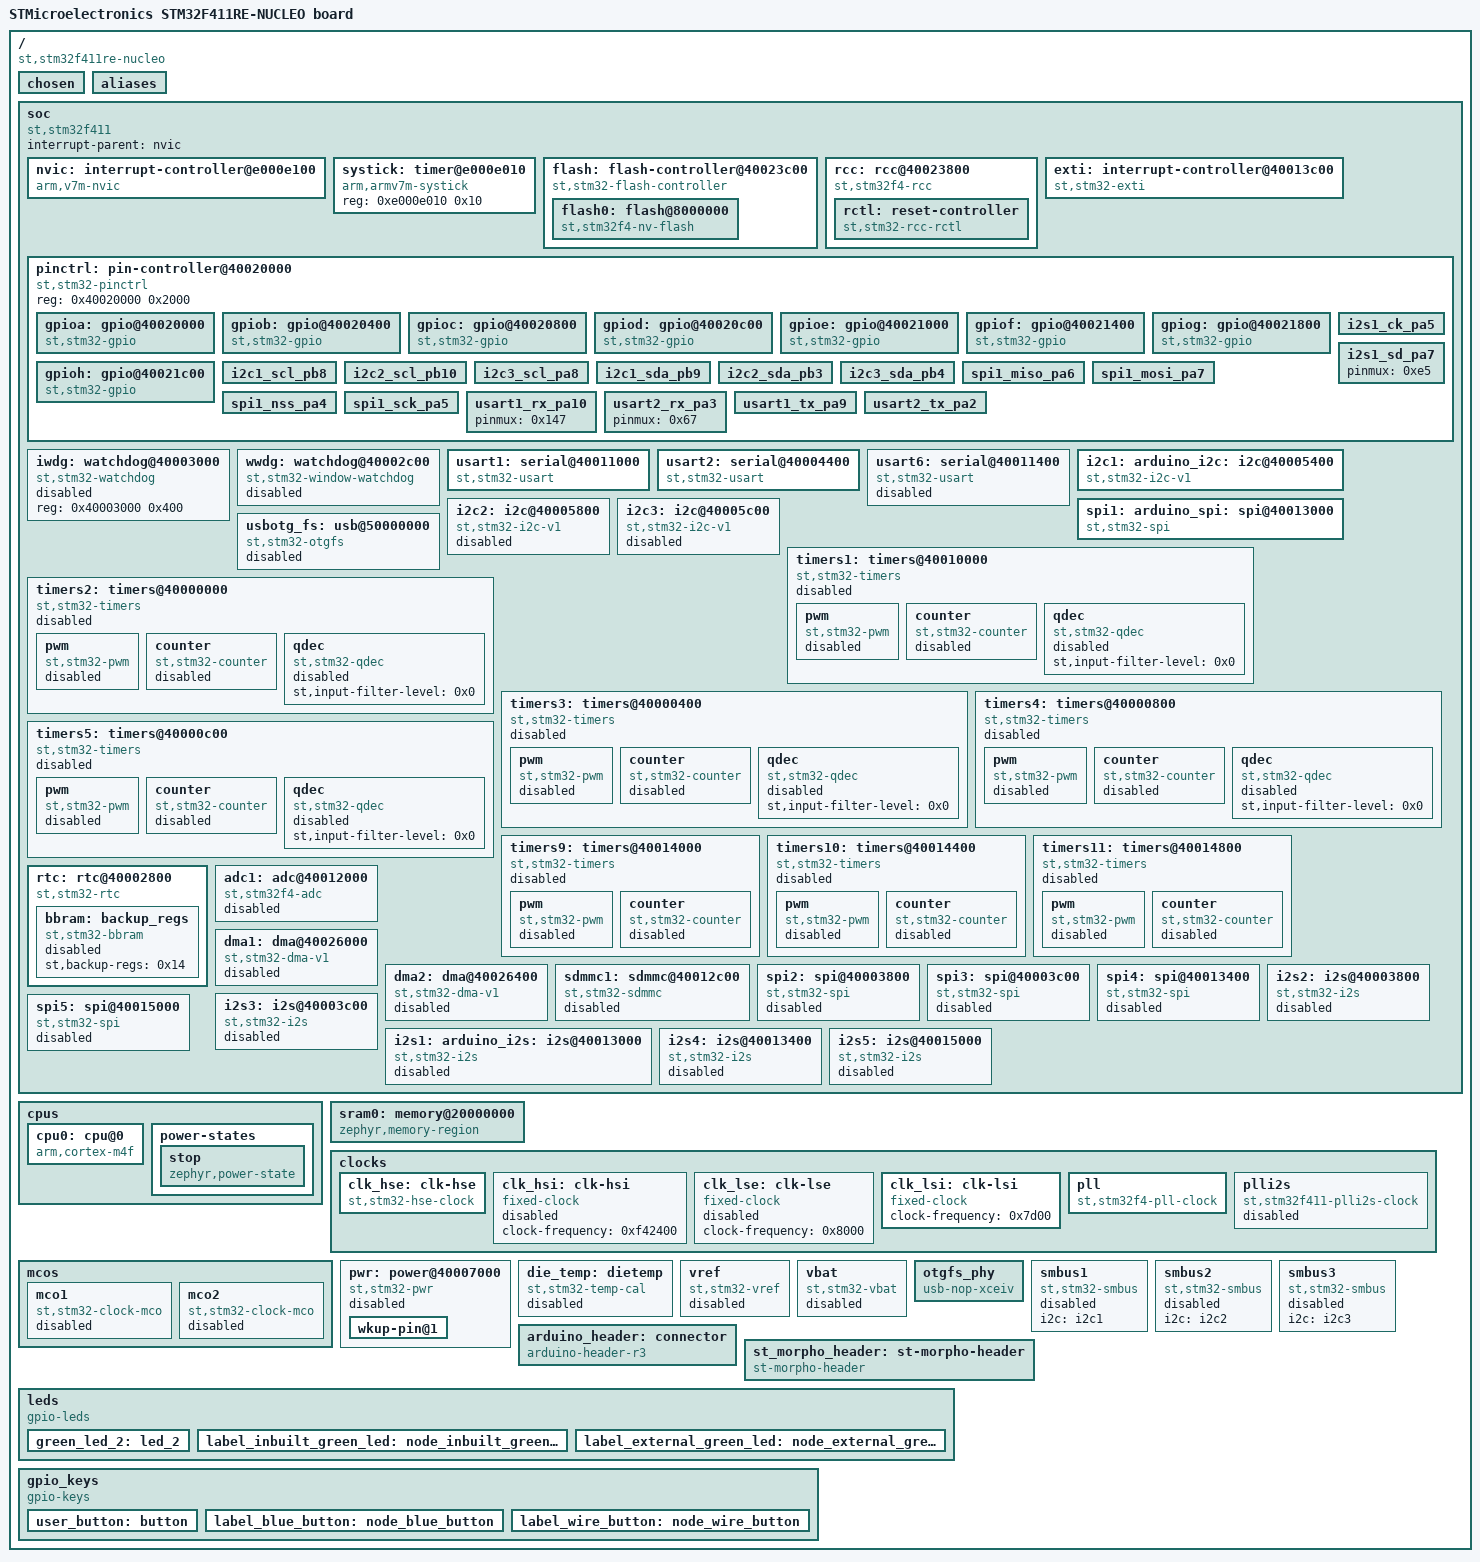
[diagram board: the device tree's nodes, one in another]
/dts-v1/;

/* node '/' defined in zephyr/dts/common/skeleton.dtsi:9 */
/ {
	model = "STMicroelectronics STM32F411RE-NUCLEO board"; /* in zephyr/boards/st/nucleo_f411re/nucleo_f411re.dts:15 */
	compatible = "st,stm32f411re-nucleo";                  /* in zephyr/boards/st/nucleo_f411re/nucleo_f411re.dts:16 */
	#address-cells = < 0x1 >;                              /* in iot/nucleo_f411re.overlay:3 */
	#size-cells = < 0x1 >;                                 /* in iot/nucleo_f411re.overlay:4 */

	/* node '/chosen' defined in zephyr/dts/common/skeleton.dtsi:13 */
	chosen {
		zephyr,flash-controller = &flash;  /* in zephyr/dts/arm/st/f4/stm32f4.dtsi:27 */
		zephyr,cortex-m-idle-timer = &rtc; /* in zephyr/dts/arm/st/f4/stm32f4.dtsi:28 */
		zephyr,console = &usart2;          /* in zephyr/boards/st/nucleo_f411re/nucleo_f411re.dts:19 */
		zephyr,shell-uart = &usart2;       /* in zephyr/boards/st/nucleo_f411re/nucleo_f411re.dts:20 */
		zephyr,sram = &sram0;              /* in zephyr/boards/st/nucleo_f411re/nucleo_f411re.dts:21 */
		zephyr,flash = &flash0;            /* in zephyr/boards/st/nucleo_f411re/nucleo_f411re.dts:22 */
	};

	/* node '/aliases' defined in zephyr/dts/common/skeleton.dtsi:15 */
	aliases {
		sw0 = &user_button;               /* in zephyr/boards/st/nucleo_f411re/nucleo_f411re.dts:46 */
		sw1 = &label_blue_button;         /* in iot/nucleo_f411re.overlay:35 */
		sw2 = &label_wire_button;         /* in iot/nucleo_f411re.overlay:36 */
		led0 = &label_inbuilt_green_led;  /* in iot/nucleo_f411re.overlay:37 */
		led1 = &label_external_green_led; /* in iot/nucleo_f411re.overlay:38 */
	};

	/* node '/soc' defined in zephyr/dts/arm/armv7-m.dtsi:6 */
	soc {
		#address-cells = < 0x1 >;     /* in zephyr/dts/arm/armv7-m.dtsi:7 */
		#size-cells = < 0x1 >;        /* in zephyr/dts/arm/armv7-m.dtsi:8 */
		interrupt-parent = < &nvic >; /* in zephyr/dts/arm/armv7-m.dtsi:10 */
		ranges;                       /* in zephyr/dts/arm/armv7-m.dtsi:11 */
		compatible = "st,stm32f411",
		             "st,stm32f4",
		             "simple-bus";    /* in zephyr/dts/arm/st/f4/stm32f411.dtsi:19 */

		/* node '/soc/interrupt-controller@e000e100' defined in zephyr/dts/arm/armv7-m.dtsi:13 */
		nvic: interrupt-controller@e000e100 {
			#address-cells = < 0x1 >;            /* in zephyr/dts/arm/armv7-m.dtsi:14 */
			compatible = "arm,v7m-nvic";         /* in zephyr/dts/arm/armv7-m.dtsi:15 */
			reg = < 0xe000e100 0xc00 >;          /* in zephyr/dts/arm/armv7-m.dtsi:16 */
			interrupt-controller;                /* in zephyr/dts/arm/armv7-m.dtsi:17 */
			#interrupt-cells = < 0x2 >;          /* in zephyr/dts/arm/armv7-m.dtsi:18 */
			arm,num-irq-priority-bits = < 0x4 >; /* in zephyr/dts/arm/st/f4/stm32f4.dtsi:682 */
			phandle = < 0x1 >;                   /* in zephyr/dts/arm/armv7-m.dtsi:10 */
		};

		/* node '/soc/timer@e000e010' defined in zephyr/dts/arm/armv7-m.dtsi:21 */
		systick: timer@e000e010 {
			compatible = "arm,armv7m-systick"; /* in zephyr/dts/arm/armv7-m.dtsi:22 */
			reg = < 0xe000e010 0x10 >;         /* in zephyr/dts/arm/armv7-m.dtsi:23 */
		};

		/* node '/soc/flash-controller@40023c00' defined in zephyr/dts/arm/st/f4/stm32f4.dtsi:111 */
		flash: flash-controller@40023c00 {
			compatible = "st,stm32-flash-controller",
			             "st,stm32f4-flash-controller"; /* in zephyr/dts/arm/st/f4/stm32f4.dtsi:112 */
			reg = < 0x40023c00 0x400 >;                 /* in zephyr/dts/arm/st/f4/stm32f4.dtsi:113 */
			interrupts = < 0x4 0x0 >;                   /* in zephyr/dts/arm/st/f4/stm32f4.dtsi:114 */
			#address-cells = < 0x1 >;                   /* in zephyr/dts/arm/st/f4/stm32f4.dtsi:116 */
			#size-cells = < 0x1 >;                      /* in zephyr/dts/arm/st/f4/stm32f4.dtsi:117 */

			/* node '/soc/flash-controller@40023c00/flash@8000000' defined in zephyr/dts/arm/st/f4/stm32f4.dtsi:119 */
			flash0: flash@8000000 {
				compatible = "st,stm32f4-nv-flash",
				             "st,stm32-nv-flash",
				             "soc-nv-flash";        /* in zephyr/dts/arm/st/f4/stm32f4.dtsi:120 */
				write-block-size = < 0x1 >;         /* in zephyr/dts/arm/st/f4/stm32f4.dtsi:123 */
				max-erase-time = < 0xfa0 >;         /* in zephyr/dts/arm/st/f4/stm32f4.dtsi:125 */
				reg = < 0x8000000 0x80000 >;        /* in zephyr/dts/arm/st/f4/stm32f411Xe.dtsi:17 */
			};
		};

		/* node '/soc/rcc@40023800' defined in zephyr/dts/arm/st/f4/stm32f4.dtsi:129 */
		rcc: rcc@40023800 {
			compatible = "st,stm32f4-rcc";   /* in zephyr/dts/arm/st/f4/stm32f4.dtsi:130 */
			#clock-cells = < 0x2 >;          /* in zephyr/dts/arm/st/f4/stm32f4.dtsi:131 */
			reg = < 0x40023800 0x400 >;      /* in zephyr/dts/arm/st/f4/stm32f4.dtsi:132 */
			clocks = < &pll >;               /* in zephyr/boards/st/nucleo_f411re/nucleo_f411re.dts:70 */
			clock-frequency = < 0x5b8d800 >; /* in zephyr/boards/st/nucleo_f411re/nucleo_f411re.dts:71 */
			ahb-prescaler = < 0x1 >;         /* in zephyr/boards/st/nucleo_f411re/nucleo_f411re.dts:72 */
			apb1-prescaler = < 0x2 >;        /* in zephyr/boards/st/nucleo_f411re/nucleo_f411re.dts:73 */
			apb2-prescaler = < 0x1 >;        /* in zephyr/boards/st/nucleo_f411re/nucleo_f411re.dts:74 */
			phandle = < 0x3 >;               /* in zephyr/dts/arm/st/f4/stm32f4.dtsi:146 */

			/* node '/soc/rcc@40023800/reset-controller' defined in zephyr/dts/arm/st/f4/stm32f4.dtsi:134 */
			rctl: reset-controller {
				compatible = "st,stm32-rcc-rctl"; /* in zephyr/dts/arm/st/f4/stm32f4.dtsi:135 */
				#reset-cells = < 0x1 >;           /* in zephyr/dts/arm/st/f4/stm32f4.dtsi:136 */
				phandle = < 0x4 >;                /* in zephyr/dts/arm/st/f4/stm32f4.dtsi:245 */
			};
		};

		/* node '/soc/interrupt-controller@40013c00' defined in zephyr/dts/arm/st/f4/stm32f4.dtsi:140 */
		exti: interrupt-controller@40013c00 {
			compatible = "st,stm32-exti";  /* in zephyr/dts/arm/st/f4/stm32f4.dtsi:141 */
			interrupt-controller;          /* in zephyr/dts/arm/st/f4/stm32f4.dtsi:142 */
			#interrupt-cells = < 0x1 >;    /* in zephyr/dts/arm/st/f4/stm32f4.dtsi:143 */
			#address-cells = < 0x0 >;      /* in zephyr/dts/arm/st/f4/stm32f4.dtsi:144 */
			reg = < 0x40013c00 0x400 >;    /* in zephyr/dts/arm/st/f4/stm32f4.dtsi:145 */
			clocks = < &rcc 0x44 0x4000 >; /* in zephyr/dts/arm/st/f4/stm32f4.dtsi:146 */
			num-lines = < 0x20 >;          /* in zephyr/dts/arm/st/f4/stm32f4.dtsi:147 */
			interrupts = < 0x6 0x0 >,
			             < 0x7 0x0 >,
			             < 0x8 0x0 >,
			             < 0x9 0x0 >,
			             < 0xa 0x0 >,
			             < 0x17 0x0 >,
			             < 0x28 0x0 >;     /* in zephyr/dts/arm/st/f4/stm32f4.dtsi:148 */
			interrupt-names = "line0",
			                  "line1",
			                  "line2",
			                  "line3",
			                  "line4",
			                  "line5-9",
			                  "line10-15"; /* in zephyr/dts/arm/st/f4/stm32f4.dtsi:150 */
			line-ranges = < 0x0 0x1 >,
			              < 0x1 0x1 >,
			              < 0x2 0x1 >,
			              < 0x3 0x1 >,
			              < 0x4 0x1 >,
			              < 0x5 0x5 >,
			              < 0xa 0x6 >;     /* in zephyr/dts/arm/st/f4/stm32f4.dtsi:152 */
		};

		/* node '/soc/pin-controller@40020000' defined in zephyr/dts/arm/st/f4/stm32f4.dtsi:156 */
		pinctrl: pin-controller@40020000 {
			compatible = "st,stm32-pinctrl"; /* in zephyr/dts/arm/st/f4/stm32f4.dtsi:157 */
			#address-cells = < 0x1 >;        /* in zephyr/dts/arm/st/f4/stm32f4.dtsi:158 */
			#size-cells = < 0x1 >;           /* in zephyr/dts/arm/st/f4/stm32f4.dtsi:159 */
			reg = < 0x40020000 0x2000 >;     /* in zephyr/dts/arm/st/f4/stm32f4.dtsi:160 */

			/* node '/soc/pin-controller@40020000/gpio@40020000' defined in zephyr/dts/arm/st/f4/stm32f4.dtsi:162 */
			gpioa: gpio@40020000 {
				compatible = "st,stm32-gpio"; /* in zephyr/dts/arm/st/f4/stm32f4.dtsi:163 */
				gpio-controller;              /* in zephyr/dts/arm/st/f4/stm32f4.dtsi:164 */
				#gpio-cells = < 0x2 >;        /* in zephyr/dts/arm/st/f4/stm32f4.dtsi:165 */
				reg = < 0x40020000 0x400 >;   /* in zephyr/dts/arm/st/f4/stm32f4.dtsi:166 */
				clocks = < &rcc 0x30 0x1 >;   /* in zephyr/dts/arm/st/f4/stm32f4.dtsi:167 */
				phandle = < 0x1a >;           /* in zephyr/dts/arm/st/f4/stm32f4.dtsi:621 */
			};

			/* node '/soc/pin-controller@40020000/gpio@40020400' defined in zephyr/dts/arm/st/f4/stm32f4.dtsi:170 */
			gpiob: gpio@40020400 {
				compatible = "st,stm32-gpio"; /* in zephyr/dts/arm/st/f4/stm32f4.dtsi:171 */
				gpio-controller;              /* in zephyr/dts/arm/st/f4/stm32f4.dtsi:172 */
				#gpio-cells = < 0x2 >;        /* in zephyr/dts/arm/st/f4/stm32f4.dtsi:173 */
				reg = < 0x40020400 0x400 >;   /* in zephyr/dts/arm/st/f4/stm32f4.dtsi:174 */
				clocks = < &rcc 0x30 0x2 >;   /* in zephyr/dts/arm/st/f4/stm32f4.dtsi:175 */
				phandle = < 0x1f >;           /* in zephyr/boards/st/nucleo_f411re/arduino_r3_connector.dtsi:15 */
			};

			/* node '/soc/pin-controller@40020000/gpio@40020800' defined in zephyr/dts/arm/st/f4/stm32f4.dtsi:178 */
			gpioc: gpio@40020800 {
				compatible = "st,stm32-gpio"; /* in zephyr/dts/arm/st/f4/stm32f4.dtsi:179 */
				gpio-controller;              /* in zephyr/dts/arm/st/f4/stm32f4.dtsi:180 */
				#gpio-cells = < 0x2 >;        /* in zephyr/dts/arm/st/f4/stm32f4.dtsi:181 */
				reg = < 0x40020800 0x400 >;   /* in zephyr/dts/arm/st/f4/stm32f4.dtsi:182 */
				clocks = < &rcc 0x30 0x4 >;   /* in zephyr/dts/arm/st/f4/stm32f4.dtsi:183 */
				phandle = < 0x20 >;           /* in zephyr/boards/st/nucleo_f411re/arduino_r3_connector.dtsi:15 */
			};

			/* node '/soc/pin-controller@40020000/gpio@40020c00' defined in zephyr/dts/arm/st/f4/stm32f4.dtsi:186 */
			gpiod: gpio@40020c00 {
				compatible = "st,stm32-gpio"; /* in zephyr/dts/arm/st/f4/stm32f4.dtsi:187 */
				gpio-controller;              /* in zephyr/dts/arm/st/f4/stm32f4.dtsi:188 */
				#gpio-cells = < 0x2 >;        /* in zephyr/dts/arm/st/f4/stm32f4.dtsi:189 */
				reg = < 0x40020c00 0x400 >;   /* in zephyr/dts/arm/st/f4/stm32f4.dtsi:190 */
				clocks = < &rcc 0x30 0x8 >;   /* in zephyr/dts/arm/st/f4/stm32f4.dtsi:191 */
				phandle = < 0x21 >;           /* in zephyr/boards/st/nucleo_f411re/st_morpho_connector.dtsi:15 */
			};

			/* node '/soc/pin-controller@40020000/gpio@40021000' defined in zephyr/dts/arm/st/f4/stm32f4.dtsi:194 */
			gpioe: gpio@40021000 {
				compatible = "st,stm32-gpio"; /* in zephyr/dts/arm/st/f4/stm32f4.dtsi:195 */
				gpio-controller;              /* in zephyr/dts/arm/st/f4/stm32f4.dtsi:196 */
				#gpio-cells = < 0x2 >;        /* in zephyr/dts/arm/st/f4/stm32f4.dtsi:197 */
				reg = < 0x40021000 0x400 >;   /* in zephyr/dts/arm/st/f4/stm32f4.dtsi:198 */
				clocks = < &rcc 0x30 0x10 >;  /* in zephyr/dts/arm/st/f4/stm32f4.dtsi:199 */
			};

			/* node '/soc/pin-controller@40020000/gpio@40021400' defined in zephyr/dts/arm/st/f4/stm32f4.dtsi:202 */
			gpiof: gpio@40021400 {
				compatible = "st,stm32-gpio"; /* in zephyr/dts/arm/st/f4/stm32f4.dtsi:203 */
				gpio-controller;              /* in zephyr/dts/arm/st/f4/stm32f4.dtsi:204 */
				#gpio-cells = < 0x2 >;        /* in zephyr/dts/arm/st/f4/stm32f4.dtsi:205 */
				reg = < 0x40021400 0x400 >;   /* in zephyr/dts/arm/st/f4/stm32f4.dtsi:206 */
				clocks = < &rcc 0x30 0x20 >;  /* in zephyr/dts/arm/st/f4/stm32f4.dtsi:207 */
			};

			/* node '/soc/pin-controller@40020000/gpio@40021800' defined in zephyr/dts/arm/st/f4/stm32f4.dtsi:210 */
			gpiog: gpio@40021800 {
				compatible = "st,stm32-gpio"; /* in zephyr/dts/arm/st/f4/stm32f4.dtsi:211 */
				gpio-controller;              /* in zephyr/dts/arm/st/f4/stm32f4.dtsi:212 */
				#gpio-cells = < 0x2 >;        /* in zephyr/dts/arm/st/f4/stm32f4.dtsi:213 */
				reg = < 0x40021800 0x400 >;   /* in zephyr/dts/arm/st/f4/stm32f4.dtsi:214 */
				clocks = < &rcc 0x30 0x40 >;  /* in zephyr/dts/arm/st/f4/stm32f4.dtsi:215 */
			};

			/* node '/soc/pin-controller@40020000/gpio@40021c00' defined in zephyr/dts/arm/st/f4/stm32f4.dtsi:218 */
			gpioh: gpio@40021c00 {
				compatible = "st,stm32-gpio"; /* in zephyr/dts/arm/st/f4/stm32f4.dtsi:219 */
				gpio-controller;              /* in zephyr/dts/arm/st/f4/stm32f4.dtsi:220 */
				#gpio-cells = < 0x2 >;        /* in zephyr/dts/arm/st/f4/stm32f4.dtsi:221 */
				reg = < 0x40021c00 0x400 >;   /* in zephyr/dts/arm/st/f4/stm32f4.dtsi:222 */
				clocks = < &rcc 0x30 0x80 >;  /* in zephyr/dts/arm/st/f4/stm32f4.dtsi:223 */
				phandle = < 0x22 >;           /* in zephyr/boards/st/nucleo_f411re/st_morpho_connector.dtsi:15 */
			};

			/* node '/soc/pin-controller@40020000/i2c1_scl_pb8' defined in modules/hal/stm32/dts/st/f4/stm32f411r(c-e)tx-pinctrl.dtsi:289 */
			i2c1_scl_pb8: i2c1_scl_pb8 {
				pinmux = < 0x304 >; /* in modules/hal/stm32/dts/st/f4/stm32f411r(c-e)tx-pinctrl.dtsi:290 */
				bias-pull-up;       /* in modules/hal/stm32/dts/st/f4/stm32f411r(c-e)tx-pinctrl.dtsi:291 */
				drive-open-drain;   /* in modules/hal/stm32/dts/st/f4/stm32f411r(c-e)tx-pinctrl.dtsi:292 */
				phandle = < 0x9 >;  /* in zephyr/boards/st/nucleo_f411re/nucleo_f411re.dts:92 */
			};

			/* node '/soc/pin-controller@40020000/i2c2_scl_pb10' defined in modules/hal/stm32/dts/st/f4/stm32f411r(c-e)tx-pinctrl.dtsi:295 */
			i2c2_scl_pb10: i2c2_scl_pb10 {
				pinmux = < 0x344 >; /* in modules/hal/stm32/dts/st/f4/stm32f411r(c-e)tx-pinctrl.dtsi:296 */
				bias-pull-up;       /* in modules/hal/stm32/dts/st/f4/stm32f411r(c-e)tx-pinctrl.dtsi:297 */
				drive-open-drain;   /* in modules/hal/stm32/dts/st/f4/stm32f411r(c-e)tx-pinctrl.dtsi:298 */
				phandle = < 0xb >;  /* in zephyr/boards/st/nucleo_f411re/nucleo_f411re.dts:99 */
			};

			/* node '/soc/pin-controller@40020000/i2c3_scl_pa8' defined in modules/hal/stm32/dts/st/f4/stm32f411r(c-e)tx-pinctrl.dtsi:301 */
			i2c3_scl_pa8: i2c3_scl_pa8 {
				pinmux = < 0x104 >; /* in modules/hal/stm32/dts/st/f4/stm32f411r(c-e)tx-pinctrl.dtsi:302 */
				bias-pull-up;       /* in modules/hal/stm32/dts/st/f4/stm32f411r(c-e)tx-pinctrl.dtsi:303 */
				drive-open-drain;   /* in modules/hal/stm32/dts/st/f4/stm32f411r(c-e)tx-pinctrl.dtsi:304 */
				phandle = < 0xd >;  /* in zephyr/boards/st/nucleo_f411re/nucleo_f411re.dts:105 */
			};

			/* node '/soc/pin-controller@40020000/i2c1_sda_pb9' defined in modules/hal/stm32/dts/st/f4/stm32f411r(c-e)tx-pinctrl.dtsi:315 */
			i2c1_sda_pb9: i2c1_sda_pb9 {
				pinmux = < 0x324 >; /* in modules/hal/stm32/dts/st/f4/stm32f411r(c-e)tx-pinctrl.dtsi:316 */
				bias-pull-up;       /* in modules/hal/stm32/dts/st/f4/stm32f411r(c-e)tx-pinctrl.dtsi:317 */
				drive-open-drain;   /* in modules/hal/stm32/dts/st/f4/stm32f411r(c-e)tx-pinctrl.dtsi:318 */
				phandle = < 0xa >;  /* in zephyr/boards/st/nucleo_f411re/nucleo_f411re.dts:92 */
			};

			/* node '/soc/pin-controller@40020000/i2c2_sda_pb3' defined in modules/hal/stm32/dts/st/f4/stm32f411r(c-e)tx-pinctrl.dtsi:321 */
			i2c2_sda_pb3: i2c2_sda_pb3 {
				pinmux = < 0x269 >; /* in modules/hal/stm32/dts/st/f4/stm32f411r(c-e)tx-pinctrl.dtsi:322 */
				bias-pull-up;       /* in modules/hal/stm32/dts/st/f4/stm32f411r(c-e)tx-pinctrl.dtsi:323 */
				drive-open-drain;   /* in modules/hal/stm32/dts/st/f4/stm32f411r(c-e)tx-pinctrl.dtsi:324 */
				phandle = < 0xc >;  /* in zephyr/boards/st/nucleo_f411re/nucleo_f411re.dts:99 */
			};

			/* node '/soc/pin-controller@40020000/i2c3_sda_pb4' defined in modules/hal/stm32/dts/st/f4/stm32f411r(c-e)tx-pinctrl.dtsi:333 */
			i2c3_sda_pb4: i2c3_sda_pb4 {
				pinmux = < 0x289 >; /* in modules/hal/stm32/dts/st/f4/stm32f411r(c-e)tx-pinctrl.dtsi:334 */
				bias-pull-up;       /* in modules/hal/stm32/dts/st/f4/stm32f411r(c-e)tx-pinctrl.dtsi:335 */
				drive-open-drain;   /* in modules/hal/stm32/dts/st/f4/stm32f411r(c-e)tx-pinctrl.dtsi:336 */
				phandle = < 0xe >;  /* in zephyr/boards/st/nucleo_f411re/nucleo_f411re.dts:105 */
			};

			/* node '/soc/pin-controller@40020000/i2s1_ck_pa5' defined in modules/hal/stm32/dts/st/f4/stm32f411r(c-e)tx-pinctrl.dtsi:370 */
			i2s1_ck_pa5: i2s1_ck_pa5 {
				pinmux = < 0xa5 >;             /* in modules/hal/stm32/dts/st/f4/stm32f411r(c-e)tx-pinctrl.dtsi:371 */
				slew-rate = "very-high-speed"; /* in modules/hal/stm32/dts/st/f4/stm32f411r(c-e)tx-pinctrl.dtsi:372 */
				phandle = < 0x16 >;            /* in zephyr/boards/st/nucleo_f411re/nucleo_f411re.dts:111 */
			};

			/* node '/soc/pin-controller@40020000/i2s1_sd_pa7' defined in modules/hal/stm32/dts/st/f4/stm32f411r(c-e)tx-pinctrl.dtsi:449 */
			i2s1_sd_pa7: i2s1_sd_pa7 {
				pinmux = < 0xe5 >;  /* in modules/hal/stm32/dts/st/f4/stm32f411r(c-e)tx-pinctrl.dtsi:450 */
				phandle = < 0x17 >; /* in zephyr/boards/st/nucleo_f411re/nucleo_f411re.dts:111 */
			};

			/* node '/soc/pin-controller@40020000/spi1_miso_pa6' defined in modules/hal/stm32/dts/st/f4/stm32f411r(c-e)tx-pinctrl.dtsi:671 */
			spi1_miso_pa6: spi1_miso_pa6 {
				pinmux = < 0xc5 >;  /* in modules/hal/stm32/dts/st/f4/stm32f411r(c-e)tx-pinctrl.dtsi:672 */
				bias-pull-down;     /* in modules/hal/stm32/dts/st/f4/stm32f411r(c-e)tx-pinctrl.dtsi:673 */
				phandle = < 0x11 >; /* in zephyr/boards/st/nucleo_f411re/nucleo_f411re.dts:116 */
			};

			/* node '/soc/pin-controller@40020000/spi1_mosi_pa7' defined in modules/hal/stm32/dts/st/f4/stm32f411r(c-e)tx-pinctrl.dtsi:713 */
			spi1_mosi_pa7: spi1_mosi_pa7 {
				pinmux = < 0xe5 >;  /* in modules/hal/stm32/dts/st/f4/stm32f411r(c-e)tx-pinctrl.dtsi:714 */
				bias-pull-down;     /* in modules/hal/stm32/dts/st/f4/stm32f411r(c-e)tx-pinctrl.dtsi:715 */
				phandle = < 0x12 >; /* in zephyr/boards/st/nucleo_f411re/nucleo_f411re.dts:116 */
			};

			/* node '/soc/pin-controller@40020000/spi1_nss_pa4' defined in modules/hal/stm32/dts/st/f4/stm32f411r(c-e)tx-pinctrl.dtsi:760 */
			spi1_nss_pa4: spi1_nss_pa4 {
				pinmux = < 0x85 >; /* in modules/hal/stm32/dts/st/f4/stm32f411r(c-e)tx-pinctrl.dtsi:761 */
				bias-pull-up;      /* in modules/hal/stm32/dts/st/f4/stm32f411r(c-e)tx-pinctrl.dtsi:762 */
				phandle = < 0xf >; /* in zephyr/boards/st/nucleo_f411re/nucleo_f411re.dts:116 */
			};

			/* node '/soc/pin-controller@40020000/spi1_sck_pa5' defined in modules/hal/stm32/dts/st/f4/stm32f411r(c-e)tx-pinctrl.dtsi:802 */
			spi1_sck_pa5: spi1_sck_pa5 {
				pinmux = < 0xa5 >;             /* in modules/hal/stm32/dts/st/f4/stm32f411r(c-e)tx-pinctrl.dtsi:803 */
				bias-pull-down;                /* in modules/hal/stm32/dts/st/f4/stm32f411r(c-e)tx-pinctrl.dtsi:804 */
				slew-rate = "very-high-speed"; /* in modules/hal/stm32/dts/st/f4/stm32f411r(c-e)tx-pinctrl.dtsi:805 */
				phandle = < 0x10 >;            /* in zephyr/boards/st/nucleo_f411re/nucleo_f411re.dts:116 */
			};

			/* node '/soc/pin-controller@40020000/usart1_rx_pa10' defined in modules/hal/stm32/dts/st/f4/stm32f411r(c-e)tx-pinctrl.dtsi:1060 */
			usart1_rx_pa10: usart1_rx_pa10 {
				pinmux = < 0x147 >; /* in modules/hal/stm32/dts/st/f4/stm32f411r(c-e)tx-pinctrl.dtsi:1061 */
				phandle = < 0x6 >;  /* in iot/nucleo_f411re.overlay:46 */
			};

			/* node '/soc/pin-controller@40020000/usart2_rx_pa3' defined in modules/hal/stm32/dts/st/f4/stm32f411r(c-e)tx-pinctrl.dtsi:1072 */
			usart2_rx_pa3: usart2_rx_pa3 {
				pinmux = < 0x67 >; /* in modules/hal/stm32/dts/st/f4/stm32f411r(c-e)tx-pinctrl.dtsi:1073 */
				phandle = < 0x8 >; /* in zephyr/boards/st/nucleo_f411re/nucleo_f411re.dts:85 */
			};

			/* node '/soc/pin-controller@40020000/usart1_tx_pa9' defined in modules/hal/stm32/dts/st/f4/stm32f411r(c-e)tx-pinctrl.dtsi:1086 */
			usart1_tx_pa9: usart1_tx_pa9 {
				pinmux = < 0x127 >; /* in modules/hal/stm32/dts/st/f4/stm32f411r(c-e)tx-pinctrl.dtsi:1087 */
				bias-pull-up;       /* in modules/hal/stm32/dts/st/f4/stm32f411r(c-e)tx-pinctrl.dtsi:1088 */
				phandle = < 0x5 >;  /* in iot/nucleo_f411re.overlay:46 */
			};

			/* node '/soc/pin-controller@40020000/usart2_tx_pa2' defined in modules/hal/stm32/dts/st/f4/stm32f411r(c-e)tx-pinctrl.dtsi:1101 */
			usart2_tx_pa2: usart2_tx_pa2 {
				pinmux = < 0x47 >; /* in modules/hal/stm32/dts/st/f4/stm32f411r(c-e)tx-pinctrl.dtsi:1102 */
				bias-pull-up;      /* in modules/hal/stm32/dts/st/f4/stm32f411r(c-e)tx-pinctrl.dtsi:1103 */
				phandle = < 0x7 >; /* in zephyr/boards/st/nucleo_f411re/nucleo_f411re.dts:85 */
			};
		};

		/* node '/soc/watchdog@40003000' defined in zephyr/dts/arm/st/f4/stm32f4.dtsi:227 */
		iwdg: watchdog@40003000 {
			compatible = "st,stm32-watchdog"; /* in zephyr/dts/arm/st/f4/stm32f4.dtsi:228 */
			reg = < 0x40003000 0x400 >;       /* in zephyr/dts/arm/st/f4/stm32f4.dtsi:229 */
			status = "disabled";              /* in zephyr/dts/arm/st/f4/stm32f4.dtsi:230 */
		};

		/* node '/soc/watchdog@40002c00' defined in zephyr/dts/arm/st/f4/stm32f4.dtsi:233 */
		wwdg: watchdog@40002c00 {
			compatible = "st,stm32-window-watchdog"; /* in zephyr/dts/arm/st/f4/stm32f4.dtsi:234 */
			reg = < 0x40002c00 0x400 >;              /* in zephyr/dts/arm/st/f4/stm32f4.dtsi:235 */
			clocks = < &rcc 0x40 0x800 >;            /* in zephyr/dts/arm/st/f4/stm32f4.dtsi:236 */
			interrupts = < 0x0 0x7 >;                /* in zephyr/dts/arm/st/f4/stm32f4.dtsi:237 */
			status = "disabled";                     /* in zephyr/dts/arm/st/f4/stm32f4.dtsi:238 */
		};

		/* node '/soc/serial@40011000' defined in zephyr/dts/arm/st/f4/stm32f4.dtsi:241 */
		usart1: serial@40011000 {
			compatible = "st,stm32-usart",
			             "st,stm32-uart";                   /* in zephyr/dts/arm/st/f4/stm32f4.dtsi:242 */
			reg = < 0x40011000 0x400 >;                     /* in zephyr/dts/arm/st/f4/stm32f4.dtsi:243 */
			clocks = < &rcc 0x44 0x10 >;                    /* in zephyr/dts/arm/st/f4/stm32f4.dtsi:244 */
			resets = < &rctl 0x484 >;                       /* in zephyr/dts/arm/st/f4/stm32f4.dtsi:245 */
			interrupts = < 0x25 0x0 >;                      /* in zephyr/dts/arm/st/f4/stm32f4.dtsi:246 */
			status = "okay";                                /* in iot/nucleo_f411re.overlay:43 */
			current-speed = < 0x1c200 >;                    /* in iot/nucleo_f411re.overlay:44 */
			pinctrl-names = "default";                      /* in iot/nucleo_f411re.overlay:45 */
			pinctrl-0 = < &usart1_tx_pa9 &usart1_rx_pa10 >; /* in iot/nucleo_f411re.overlay:46 */
		};

		/* node '/soc/serial@40004400' defined in zephyr/dts/arm/st/f4/stm32f4.dtsi:250 */
		usart2: serial@40004400 {
			compatible = "st,stm32-usart",
			             "st,stm32-uart";                  /* in zephyr/dts/arm/st/f4/stm32f4.dtsi:251 */
			reg = < 0x40004400 0x400 >;                    /* in zephyr/dts/arm/st/f4/stm32f4.dtsi:252 */
			clocks = < &rcc 0x40 0x20000 >;                /* in zephyr/dts/arm/st/f4/stm32f4.dtsi:253 */
			resets = < &rctl 0x411 >;                      /* in zephyr/dts/arm/st/f4/stm32f4.dtsi:254 */
			interrupts = < 0x26 0x0 >;                     /* in zephyr/dts/arm/st/f4/stm32f4.dtsi:255 */
			pinctrl-0 = < &usart2_tx_pa2 &usart2_rx_pa3 >; /* in zephyr/boards/st/nucleo_f411re/nucleo_f411re.dts:85 */
			pinctrl-names = "default";                     /* in zephyr/boards/st/nucleo_f411re/nucleo_f411re.dts:86 */
			current-speed = < 0x1c200 >;                   /* in zephyr/boards/st/nucleo_f411re/nucleo_f411re.dts:87 */
			status = "okay";                               /* in zephyr/boards/st/nucleo_f411re/nucleo_f411re.dts:88 */
		};

		/* node '/soc/serial@40011400' defined in zephyr/dts/arm/st/f4/stm32f4.dtsi:259 */
		usart6: serial@40011400 {
			compatible = "st,stm32-usart",
			             "st,stm32-uart";  /* in zephyr/dts/arm/st/f4/stm32f4.dtsi:260 */
			reg = < 0x40011400 0x400 >;    /* in zephyr/dts/arm/st/f4/stm32f4.dtsi:261 */
			clocks = < &rcc 0x44 0x20 >;   /* in zephyr/dts/arm/st/f4/stm32f4.dtsi:262 */
			resets = < &rctl 0x485 >;      /* in zephyr/dts/arm/st/f4/stm32f4.dtsi:263 */
			interrupts = < 0x47 0x0 >;     /* in zephyr/dts/arm/st/f4/stm32f4.dtsi:264 */
			status = "disabled";           /* in zephyr/dts/arm/st/f4/stm32f4.dtsi:265 */
		};

		/* node '/soc/i2c@40005400' defined in zephyr/dts/arm/st/f4/stm32f4.dtsi:268 */
		i2c1: arduino_i2c: i2c@40005400 {
			compatible = "st,stm32-i2c-v1";              /* in zephyr/dts/arm/st/f4/stm32f4.dtsi:269 */
			#address-cells = < 0x1 >;                    /* in zephyr/dts/arm/st/f4/stm32f4.dtsi:271 */
			#size-cells = < 0x0 >;                       /* in zephyr/dts/arm/st/f4/stm32f4.dtsi:272 */
			reg = < 0x40005400 0x400 >;                  /* in zephyr/dts/arm/st/f4/stm32f4.dtsi:273 */
			clocks = < &rcc 0x40 0x200000 >;             /* in zephyr/dts/arm/st/f4/stm32f4.dtsi:274 */
			interrupts = < 0x1f 0x0 >,
			             < 0x20 0x0 >;                   /* in zephyr/dts/arm/st/f4/stm32f4.dtsi:275 */
			interrupt-names = "event",
			                  "error";                   /* in zephyr/dts/arm/st/f4/stm32f4.dtsi:276 */
			pinctrl-0 = < &i2c1_scl_pb8 &i2c1_sda_pb9 >; /* in zephyr/boards/st/nucleo_f411re/nucleo_f411re.dts:92 */
			pinctrl-names = "default";                   /* in zephyr/boards/st/nucleo_f411re/nucleo_f411re.dts:93 */
			status = "okay";                             /* in zephyr/boards/st/nucleo_f411re/nucleo_f411re.dts:94 */
			clock-frequency = < 0x61a80 >;               /* in zephyr/boards/st/nucleo_f411re/nucleo_f411re.dts:95 */
			phandle = < 0x1c >;                          /* in zephyr/dts/arm/st/f4/stm32f4.dtsi:660 */
		};

		/* node '/soc/i2c@40005800' defined in zephyr/dts/arm/st/f4/stm32f4.dtsi:280 */
		i2c2: i2c@40005800 {
			compatible = "st,stm32-i2c-v1";               /* in zephyr/dts/arm/st/f4/stm32f4.dtsi:281 */
			#address-cells = < 0x1 >;                     /* in zephyr/dts/arm/st/f4/stm32f4.dtsi:283 */
			#size-cells = < 0x0 >;                        /* in zephyr/dts/arm/st/f4/stm32f4.dtsi:284 */
			reg = < 0x40005800 0x400 >;                   /* in zephyr/dts/arm/st/f4/stm32f4.dtsi:285 */
			clocks = < &rcc 0x40 0x400000 >;              /* in zephyr/dts/arm/st/f4/stm32f4.dtsi:286 */
			interrupts = < 0x21 0x0 >,
			             < 0x22 0x0 >;                    /* in zephyr/dts/arm/st/f4/stm32f4.dtsi:287 */
			interrupt-names = "event",
			                  "error";                    /* in zephyr/dts/arm/st/f4/stm32f4.dtsi:288 */
			status = "disabled";                          /* in zephyr/dts/arm/st/f4/stm32f4.dtsi:289 */
			pinctrl-0 = < &i2c2_scl_pb10 &i2c2_sda_pb3 >; /* in zephyr/boards/st/nucleo_f411re/nucleo_f411re.dts:99 */
			pinctrl-names = "default";                    /* in zephyr/boards/st/nucleo_f411re/nucleo_f411re.dts:100 */
			clock-frequency = < 0x61a80 >;                /* in zephyr/boards/st/nucleo_f411re/nucleo_f411re.dts:101 */
			phandle = < 0x1d >;                           /* in zephyr/dts/arm/st/f4/stm32f4.dtsi:668 */
		};

		/* node '/soc/i2c@40005c00' defined in zephyr/dts/arm/st/f4/stm32f4.dtsi:292 */
		i2c3: i2c@40005c00 {
			compatible = "st,stm32-i2c-v1";              /* in zephyr/dts/arm/st/f4/stm32f4.dtsi:293 */
			#address-cells = < 0x1 >;                    /* in zephyr/dts/arm/st/f4/stm32f4.dtsi:295 */
			#size-cells = < 0x0 >;                       /* in zephyr/dts/arm/st/f4/stm32f4.dtsi:296 */
			reg = < 0x40005c00 0x400 >;                  /* in zephyr/dts/arm/st/f4/stm32f4.dtsi:297 */
			clocks = < &rcc 0x40 0x800000 >;             /* in zephyr/dts/arm/st/f4/stm32f4.dtsi:298 */
			interrupts = < 0x48 0x0 >,
			             < 0x49 0x0 >;                   /* in zephyr/dts/arm/st/f4/stm32f4.dtsi:299 */
			interrupt-names = "event",
			                  "error";                   /* in zephyr/dts/arm/st/f4/stm32f4.dtsi:300 */
			status = "disabled";                         /* in zephyr/dts/arm/st/f4/stm32f4.dtsi:301 */
			pinctrl-0 = < &i2c3_scl_pa8 &i2c3_sda_pb4 >; /* in zephyr/boards/st/nucleo_f411re/nucleo_f411re.dts:105 */
			pinctrl-names = "default";                   /* in zephyr/boards/st/nucleo_f411re/nucleo_f411re.dts:106 */
			clock-frequency = < 0x61a80 >;               /* in zephyr/boards/st/nucleo_f411re/nucleo_f411re.dts:107 */
			phandle = < 0x1e >;                          /* in zephyr/dts/arm/st/f4/stm32f4.dtsi:676 */
		};

		/* node '/soc/spi@40013000' defined in zephyr/dts/arm/st/f4/stm32f4.dtsi:304 */
		spi1: arduino_spi: spi@40013000 {
			compatible = "st,stm32-spi";                                               /* in zephyr/dts/arm/st/f4/stm32f4.dtsi:305 */
			#address-cells = < 0x1 >;                                                  /* in zephyr/dts/arm/st/f4/stm32f4.dtsi:306 */
			#size-cells = < 0x0 >;                                                     /* in zephyr/dts/arm/st/f4/stm32f4.dtsi:307 */
			reg = < 0x40013000 0x400 >;                                                /* in zephyr/dts/arm/st/f4/stm32f4.dtsi:308 */
			clocks = < &rcc 0x44 0x1000 >;                                             /* in zephyr/dts/arm/st/f4/stm32f4.dtsi:309 */
			interrupts = < 0x23 0x5 >;                                                 /* in zephyr/dts/arm/st/f4/stm32f4.dtsi:310 */
			st,spi-data-width = "limited-8-16-bit";                                    /* in zephyr/dts/arm/st/f4/stm32f4.dtsi:311 */
			pinctrl-0 = < &spi1_nss_pa4 &spi1_sck_pa5 &spi1_miso_pa6 &spi1_mosi_pa7 >; /* in zephyr/boards/st/nucleo_f411re/nucleo_f411re.dts:116 */
			pinctrl-names = "default";                                                 /* in zephyr/boards/st/nucleo_f411re/nucleo_f411re.dts:118 */
			status = "okay";                                                           /* in zephyr/boards/st/nucleo_f411re/nucleo_f411re.dts:119 */
		};

		/* node '/soc/usb@50000000' defined in zephyr/dts/arm/st/f4/stm32f4.dtsi:315 */
		usbotg_fs: usb@50000000 {
			compatible = "st,stm32-otgfs"; /* in zephyr/dts/arm/st/f4/stm32f4.dtsi:316 */
			reg = < 0x50000000 0x40000 >;  /* in zephyr/dts/arm/st/f4/stm32f4.dtsi:317 */
			interrupts = < 0x43 0x0 >;     /* in zephyr/dts/arm/st/f4/stm32f4.dtsi:318 */
			interrupt-names = "otgfs";     /* in zephyr/dts/arm/st/f4/stm32f4.dtsi:319 */
			num-bidir-endpoints = < 0x4 >; /* in zephyr/dts/arm/st/f4/stm32f4.dtsi:320 */
			ram-size = < 0x500 >;          /* in zephyr/dts/arm/st/f4/stm32f4.dtsi:321 */
			maximum-speed = "full-speed";  /* in zephyr/dts/arm/st/f4/stm32f4.dtsi:322 */
			phys = < &otgfs_phy >;         /* in zephyr/dts/arm/st/f4/stm32f4.dtsi:323 */
			clocks = < &rcc 0x34 0x80 >,
			         < &rcc 0x7 0xff >;    /* in zephyr/dts/arm/st/f4/stm32f4.dtsi:324 */
			status = "disabled";           /* in zephyr/dts/arm/st/f4/stm32f4.dtsi:326 */
		};

		/* node '/soc/timers@40010000' defined in zephyr/dts/arm/st/f4/stm32f4.dtsi:329 */
		timers1: timers@40010000 {
			compatible = "st,stm32-timers"; /* in zephyr/dts/arm/st/f4/stm32f4.dtsi:330 */
			reg = < 0x40010000 0x400 >;     /* in zephyr/dts/arm/st/f4/stm32f4.dtsi:331 */
			clocks = < &rcc 0x44 0x1 >,
			         < &rcc 0xd 0xff >;     /* in zephyr/dts/arm/st/f4/stm32f4.dtsi:332 */
			resets = < &rctl 0x480 >;       /* in zephyr/dts/arm/st/f4/stm32f4.dtsi:334 */
			interrupts = < 0x18 0x0 >,
			             < 0x19 0x0 >,
			             < 0x1a 0x0 >,
			             < 0x1b 0x0 >;      /* in zephyr/dts/arm/st/f4/stm32f4.dtsi:335 */
			interrupt-names = "brk",
			                  "up",
			                  "trgcom",
			                  "cc";         /* in zephyr/dts/arm/st/f4/stm32f4.dtsi:336 */
			st,prescaler = < 0x0 >;         /* in zephyr/dts/arm/st/f4/stm32f4.dtsi:337 */
			status = "disabled";            /* in zephyr/dts/arm/st/f4/stm32f4.dtsi:338 */

			/* node '/soc/timers@40010000/pwm' defined in zephyr/dts/arm/st/f4/stm32f4.dtsi:340 */
			pwm {
				compatible = "st,stm32-pwm"; /* in zephyr/dts/arm/st/f4/stm32f4.dtsi:341 */
				status = "disabled";         /* in zephyr/dts/arm/st/f4/stm32f4.dtsi:342 */
				#pwm-cells = < 0x3 >;        /* in zephyr/dts/arm/st/f4/stm32f4.dtsi:343 */
			};

			/* node '/soc/timers@40010000/counter' defined in zephyr/dts/arm/st/f4/stm32f4.dtsi:346 */
			counter {
				compatible = "st,stm32-counter"; /* in zephyr/dts/arm/st/f4/stm32f4.dtsi:347 */
				status = "disabled";             /* in zephyr/dts/arm/st/f4/stm32f4.dtsi:348 */
			};

			/* node '/soc/timers@40010000/qdec' defined in zephyr/dts/arm/st/f4/stm32f4.dtsi:351 */
			qdec {
				compatible = "st,stm32-qdec";    /* in zephyr/dts/arm/st/f4/stm32f4.dtsi:352 */
				st,input-filter-level = < 0x0 >; /* in zephyr/dts/arm/st/f4/stm32f4.dtsi:353 */
				status = "disabled";             /* in zephyr/dts/arm/st/f4/stm32f4.dtsi:354 */
			};
		};

		/* node '/soc/timers@40000000' defined in zephyr/dts/arm/st/f4/stm32f4.dtsi:358 */
		timers2: timers@40000000 {
			compatible = "st,stm32-timers"; /* in zephyr/dts/arm/st/f4/stm32f4.dtsi:359 */
			reg = < 0x40000000 0x400 >;     /* in zephyr/dts/arm/st/f4/stm32f4.dtsi:360 */
			clocks = < &rcc 0x40 0x1 >,
			         < &rcc 0xc 0xff >;     /* in zephyr/dts/arm/st/f4/stm32f4.dtsi:361 */
			resets = < &rctl 0x400 >;       /* in zephyr/dts/arm/st/f4/stm32f4.dtsi:363 */
			interrupts = < 0x1c 0x0 >;      /* in zephyr/dts/arm/st/f4/stm32f4.dtsi:364 */
			interrupt-names = "global";     /* in zephyr/dts/arm/st/f4/stm32f4.dtsi:365 */
			st,prescaler = < 0x0 >;         /* in zephyr/dts/arm/st/f4/stm32f4.dtsi:366 */
			status = "disabled";            /* in zephyr/dts/arm/st/f4/stm32f4.dtsi:367 */

			/* node '/soc/timers@40000000/pwm' defined in zephyr/dts/arm/st/f4/stm32f4.dtsi:369 */
			pwm {
				compatible = "st,stm32-pwm"; /* in zephyr/dts/arm/st/f4/stm32f4.dtsi:370 */
				status = "disabled";         /* in zephyr/dts/arm/st/f4/stm32f4.dtsi:371 */
				#pwm-cells = < 0x3 >;        /* in zephyr/dts/arm/st/f4/stm32f4.dtsi:372 */
			};

			/* node '/soc/timers@40000000/counter' defined in zephyr/dts/arm/st/f4/stm32f4.dtsi:375 */
			counter {
				compatible = "st,stm32-counter"; /* in zephyr/dts/arm/st/f4/stm32f4.dtsi:376 */
				status = "disabled";             /* in zephyr/dts/arm/st/f4/stm32f4.dtsi:377 */
			};

			/* node '/soc/timers@40000000/qdec' defined in zephyr/dts/arm/st/f4/stm32f4.dtsi:380 */
			qdec {
				compatible = "st,stm32-qdec";    /* in zephyr/dts/arm/st/f4/stm32f4.dtsi:381 */
				st,input-filter-level = < 0x0 >; /* in zephyr/dts/arm/st/f4/stm32f4.dtsi:382 */
				status = "disabled";             /* in zephyr/dts/arm/st/f4/stm32f4.dtsi:383 */
			};
		};

		/* node '/soc/timers@40000400' defined in zephyr/dts/arm/st/f4/stm32f4.dtsi:387 */
		timers3: timers@40000400 {
			compatible = "st,stm32-timers"; /* in zephyr/dts/arm/st/f4/stm32f4.dtsi:388 */
			reg = < 0x40000400 0x400 >;     /* in zephyr/dts/arm/st/f4/stm32f4.dtsi:389 */
			clocks = < &rcc 0x40 0x2 >,
			         < &rcc 0xc 0xff >;     /* in zephyr/dts/arm/st/f4/stm32f4.dtsi:390 */
			resets = < &rctl 0x401 >;       /* in zephyr/dts/arm/st/f4/stm32f4.dtsi:392 */
			interrupts = < 0x1d 0x0 >;      /* in zephyr/dts/arm/st/f4/stm32f4.dtsi:393 */
			interrupt-names = "global";     /* in zephyr/dts/arm/st/f4/stm32f4.dtsi:394 */
			st,prescaler = < 0x0 >;         /* in zephyr/dts/arm/st/f4/stm32f4.dtsi:395 */
			status = "disabled";            /* in zephyr/dts/arm/st/f4/stm32f4.dtsi:396 */

			/* node '/soc/timers@40000400/pwm' defined in zephyr/dts/arm/st/f4/stm32f4.dtsi:398 */
			pwm {
				compatible = "st,stm32-pwm"; /* in zephyr/dts/arm/st/f4/stm32f4.dtsi:399 */
				status = "disabled";         /* in zephyr/dts/arm/st/f4/stm32f4.dtsi:400 */
				#pwm-cells = < 0x3 >;        /* in zephyr/dts/arm/st/f4/stm32f4.dtsi:401 */
			};

			/* node '/soc/timers@40000400/counter' defined in zephyr/dts/arm/st/f4/stm32f4.dtsi:404 */
			counter {
				compatible = "st,stm32-counter"; /* in zephyr/dts/arm/st/f4/stm32f4.dtsi:405 */
				status = "disabled";             /* in zephyr/dts/arm/st/f4/stm32f4.dtsi:406 */
			};

			/* node '/soc/timers@40000400/qdec' defined in zephyr/dts/arm/st/f4/stm32f4.dtsi:409 */
			qdec {
				compatible = "st,stm32-qdec";    /* in zephyr/dts/arm/st/f4/stm32f4.dtsi:410 */
				st,input-filter-level = < 0x0 >; /* in zephyr/dts/arm/st/f4/stm32f4.dtsi:411 */
				status = "disabled";             /* in zephyr/dts/arm/st/f4/stm32f4.dtsi:412 */
			};
		};

		/* node '/soc/timers@40000800' defined in zephyr/dts/arm/st/f4/stm32f4.dtsi:416 */
		timers4: timers@40000800 {
			compatible = "st,stm32-timers"; /* in zephyr/dts/arm/st/f4/stm32f4.dtsi:417 */
			reg = < 0x40000800 0x400 >;     /* in zephyr/dts/arm/st/f4/stm32f4.dtsi:418 */
			clocks = < &rcc 0x40 0x4 >,
			         < &rcc 0xc 0xff >;     /* in zephyr/dts/arm/st/f4/stm32f4.dtsi:419 */
			resets = < &rctl 0x402 >;       /* in zephyr/dts/arm/st/f4/stm32f4.dtsi:421 */
			interrupts = < 0x1e 0x0 >;      /* in zephyr/dts/arm/st/f4/stm32f4.dtsi:422 */
			interrupt-names = "global";     /* in zephyr/dts/arm/st/f4/stm32f4.dtsi:423 */
			st,prescaler = < 0x0 >;         /* in zephyr/dts/arm/st/f4/stm32f4.dtsi:424 */
			status = "disabled";            /* in zephyr/dts/arm/st/f4/stm32f4.dtsi:425 */

			/* node '/soc/timers@40000800/pwm' defined in zephyr/dts/arm/st/f4/stm32f4.dtsi:427 */
			pwm {
				compatible = "st,stm32-pwm"; /* in zephyr/dts/arm/st/f4/stm32f4.dtsi:428 */
				status = "disabled";         /* in zephyr/dts/arm/st/f4/stm32f4.dtsi:429 */
				#pwm-cells = < 0x3 >;        /* in zephyr/dts/arm/st/f4/stm32f4.dtsi:430 */
			};

			/* node '/soc/timers@40000800/counter' defined in zephyr/dts/arm/st/f4/stm32f4.dtsi:433 */
			counter {
				compatible = "st,stm32-counter"; /* in zephyr/dts/arm/st/f4/stm32f4.dtsi:434 */
				status = "disabled";             /* in zephyr/dts/arm/st/f4/stm32f4.dtsi:435 */
			};

			/* node '/soc/timers@40000800/qdec' defined in zephyr/dts/arm/st/f4/stm32f4.dtsi:438 */
			qdec {
				compatible = "st,stm32-qdec";    /* in zephyr/dts/arm/st/f4/stm32f4.dtsi:439 */
				st,input-filter-level = < 0x0 >; /* in zephyr/dts/arm/st/f4/stm32f4.dtsi:440 */
				status = "disabled";             /* in zephyr/dts/arm/st/f4/stm32f4.dtsi:441 */
			};
		};

		/* node '/soc/timers@40000c00' defined in zephyr/dts/arm/st/f4/stm32f4.dtsi:445 */
		timers5: timers@40000c00 {
			compatible = "st,stm32-timers"; /* in zephyr/dts/arm/st/f4/stm32f4.dtsi:446 */
			reg = < 0x40000c00 0x400 >;     /* in zephyr/dts/arm/st/f4/stm32f4.dtsi:447 */
			clocks = < &rcc 0x40 0x8 >,
			         < &rcc 0xc 0xff >;     /* in zephyr/dts/arm/st/f4/stm32f4.dtsi:448 */
			resets = < &rctl 0x403 >;       /* in zephyr/dts/arm/st/f4/stm32f4.dtsi:450 */
			interrupts = < 0x32 0x0 >;      /* in zephyr/dts/arm/st/f4/stm32f4.dtsi:451 */
			interrupt-names = "global";     /* in zephyr/dts/arm/st/f4/stm32f4.dtsi:452 */
			st,prescaler = < 0x0 >;         /* in zephyr/dts/arm/st/f4/stm32f4.dtsi:453 */
			status = "disabled";            /* in zephyr/dts/arm/st/f4/stm32f4.dtsi:454 */

			/* node '/soc/timers@40000c00/pwm' defined in zephyr/dts/arm/st/f4/stm32f4.dtsi:456 */
			pwm {
				compatible = "st,stm32-pwm"; /* in zephyr/dts/arm/st/f4/stm32f4.dtsi:457 */
				status = "disabled";         /* in zephyr/dts/arm/st/f4/stm32f4.dtsi:458 */
				#pwm-cells = < 0x3 >;        /* in zephyr/dts/arm/st/f4/stm32f4.dtsi:459 */
			};

			/* node '/soc/timers@40000c00/counter' defined in zephyr/dts/arm/st/f4/stm32f4.dtsi:462 */
			counter {
				compatible = "st,stm32-counter"; /* in zephyr/dts/arm/st/f4/stm32f4.dtsi:463 */
				status = "disabled";             /* in zephyr/dts/arm/st/f4/stm32f4.dtsi:464 */
			};

			/* node '/soc/timers@40000c00/qdec' defined in zephyr/dts/arm/st/f4/stm32f4.dtsi:467 */
			qdec {
				compatible = "st,stm32-qdec";    /* in zephyr/dts/arm/st/f4/stm32f4.dtsi:468 */
				st,input-filter-level = < 0x0 >; /* in zephyr/dts/arm/st/f4/stm32f4.dtsi:469 */
				status = "disabled";             /* in zephyr/dts/arm/st/f4/stm32f4.dtsi:470 */
			};
		};

		/* node '/soc/timers@40014000' defined in zephyr/dts/arm/st/f4/stm32f4.dtsi:474 */
		timers9: timers@40014000 {
			compatible = "st,stm32-timers"; /* in zephyr/dts/arm/st/f4/stm32f4.dtsi:475 */
			reg = < 0x40014000 0x400 >;     /* in zephyr/dts/arm/st/f4/stm32f4.dtsi:476 */
			clocks = < &rcc 0x44 0x10000 >,
			         < &rcc 0xd 0xff >;     /* in zephyr/dts/arm/st/f4/stm32f4.dtsi:477 */
			resets = < &rctl 0x490 >;       /* in zephyr/dts/arm/st/f4/stm32f4.dtsi:479 */
			interrupts = < 0x18 0x0 >;      /* in zephyr/dts/arm/st/f4/stm32f4.dtsi:480 */
			interrupt-names = "global";     /* in zephyr/dts/arm/st/f4/stm32f4.dtsi:481 */
			st,prescaler = < 0x0 >;         /* in zephyr/dts/arm/st/f4/stm32f4.dtsi:482 */
			status = "disabled";            /* in zephyr/dts/arm/st/f4/stm32f4.dtsi:483 */

			/* node '/soc/timers@40014000/pwm' defined in zephyr/dts/arm/st/f4/stm32f4.dtsi:485 */
			pwm {
				compatible = "st,stm32-pwm"; /* in zephyr/dts/arm/st/f4/stm32f4.dtsi:486 */
				status = "disabled";         /* in zephyr/dts/arm/st/f4/stm32f4.dtsi:487 */
				#pwm-cells = < 0x3 >;        /* in zephyr/dts/arm/st/f4/stm32f4.dtsi:488 */
			};

			/* node '/soc/timers@40014000/counter' defined in zephyr/dts/arm/st/f4/stm32f4.dtsi:491 */
			counter {
				compatible = "st,stm32-counter"; /* in zephyr/dts/arm/st/f4/stm32f4.dtsi:492 */
				status = "disabled";             /* in zephyr/dts/arm/st/f4/stm32f4.dtsi:493 */
			};
		};

		/* node '/soc/timers@40014400' defined in zephyr/dts/arm/st/f4/stm32f4.dtsi:497 */
		timers10: timers@40014400 {
			compatible = "st,stm32-timers"; /* in zephyr/dts/arm/st/f4/stm32f4.dtsi:498 */
			reg = < 0x40014400 0x400 >;     /* in zephyr/dts/arm/st/f4/stm32f4.dtsi:499 */
			clocks = < &rcc 0x44 0x20000 >,
			         < &rcc 0xd 0xff >;     /* in zephyr/dts/arm/st/f4/stm32f4.dtsi:500 */
			resets = < &rctl 0x491 >;       /* in zephyr/dts/arm/st/f4/stm32f4.dtsi:502 */
			interrupts = < 0x19 0x0 >;      /* in zephyr/dts/arm/st/f4/stm32f4.dtsi:503 */
			interrupt-names = "global";     /* in zephyr/dts/arm/st/f4/stm32f4.dtsi:504 */
			st,prescaler = < 0x0 >;         /* in zephyr/dts/arm/st/f4/stm32f4.dtsi:505 */
			status = "disabled";            /* in zephyr/dts/arm/st/f4/stm32f4.dtsi:506 */

			/* node '/soc/timers@40014400/pwm' defined in zephyr/dts/arm/st/f4/stm32f4.dtsi:508 */
			pwm {
				compatible = "st,stm32-pwm"; /* in zephyr/dts/arm/st/f4/stm32f4.dtsi:509 */
				status = "disabled";         /* in zephyr/dts/arm/st/f4/stm32f4.dtsi:510 */
				#pwm-cells = < 0x3 >;        /* in zephyr/dts/arm/st/f4/stm32f4.dtsi:511 */
			};

			/* node '/soc/timers@40014400/counter' defined in zephyr/dts/arm/st/f4/stm32f4.dtsi:514 */
			counter {
				compatible = "st,stm32-counter"; /* in zephyr/dts/arm/st/f4/stm32f4.dtsi:515 */
				status = "disabled";             /* in zephyr/dts/arm/st/f4/stm32f4.dtsi:516 */
			};
		};

		/* node '/soc/timers@40014800' defined in zephyr/dts/arm/st/f4/stm32f4.dtsi:520 */
		timers11: timers@40014800 {
			compatible = "st,stm32-timers"; /* in zephyr/dts/arm/st/f4/stm32f4.dtsi:521 */
			reg = < 0x40014800 0x400 >;     /* in zephyr/dts/arm/st/f4/stm32f4.dtsi:522 */
			clocks = < &rcc 0x44 0x40000 >,
			         < &rcc 0xd 0xff >;     /* in zephyr/dts/arm/st/f4/stm32f4.dtsi:523 */
			resets = < &rctl 0x492 >;       /* in zephyr/dts/arm/st/f4/stm32f4.dtsi:525 */
			interrupts = < 0x1a 0x0 >;      /* in zephyr/dts/arm/st/f4/stm32f4.dtsi:526 */
			interrupt-names = "global";     /* in zephyr/dts/arm/st/f4/stm32f4.dtsi:527 */
			st,prescaler = < 0x0 >;         /* in zephyr/dts/arm/st/f4/stm32f4.dtsi:528 */
			status = "disabled";            /* in zephyr/dts/arm/st/f4/stm32f4.dtsi:529 */

			/* node '/soc/timers@40014800/pwm' defined in zephyr/dts/arm/st/f4/stm32f4.dtsi:531 */
			pwm {
				compatible = "st,stm32-pwm"; /* in zephyr/dts/arm/st/f4/stm32f4.dtsi:532 */
				status = "disabled";         /* in zephyr/dts/arm/st/f4/stm32f4.dtsi:533 */
				#pwm-cells = < 0x3 >;        /* in zephyr/dts/arm/st/f4/stm32f4.dtsi:534 */
			};

			/* node '/soc/timers@40014800/counter' defined in zephyr/dts/arm/st/f4/stm32f4.dtsi:537 */
			counter {
				compatible = "st,stm32-counter"; /* in zephyr/dts/arm/st/f4/stm32f4.dtsi:538 */
				status = "disabled";             /* in zephyr/dts/arm/st/f4/stm32f4.dtsi:539 */
			};
		};

		/* node '/soc/rtc@40002800' defined in zephyr/dts/arm/st/f4/stm32f4.dtsi:543 */
		rtc: rtc@40002800 {
			compatible = "st,stm32-rtc";       /* in zephyr/dts/arm/st/f4/stm32f4.dtsi:544 */
			reg = < 0x40002800 0x400 >;        /* in zephyr/dts/arm/st/f4/stm32f4.dtsi:545 */
			interrupts = < 0x29 0x0 >;         /* in zephyr/dts/arm/st/f4/stm32f4.dtsi:546 */
			prescaler = < 0x8000 >;            /* in zephyr/dts/arm/st/f4/stm32f4.dtsi:548 */
			alarms-count = < 0x2 >;            /* in zephyr/dts/arm/st/f4/stm32f4.dtsi:549 */
			alrm-exti-line = < 0x11 >;         /* in zephyr/dts/arm/st/f4/stm32f4.dtsi:550 */
			clocks = < &rcc 0x40 0x10000000 >,
			         < &rcc 0x3 0x2280070 >;   /* in zephyr/boards/st/nucleo_f411re/nucleo_f411re.dts:123 */
			status = "okay";                   /* in zephyr/boards/st/nucleo_f411re/nucleo_f411re.dts:125 */

			/* node '/soc/rtc@40002800/backup_regs' defined in zephyr/dts/arm/st/f4/stm32f4.dtsi:553 */
			bbram: backup_regs {
				compatible = "st,stm32-bbram"; /* in zephyr/dts/arm/st/f4/stm32f4.dtsi:554 */
				st,backup-regs = < 0x14 >;     /* in zephyr/dts/arm/st/f4/stm32f4.dtsi:555 */
				status = "disabled";           /* in zephyr/dts/arm/st/f4/stm32f4.dtsi:556 */
			};
		};

		/* node '/soc/adc@40012000' defined in zephyr/dts/arm/st/f4/stm32f4.dtsi:560 */
		adc1: adc@40012000 {
			compatible = "st,stm32f4-adc",
			             "st,stm32-adc";                                 /* in zephyr/dts/arm/st/f4/stm32f4.dtsi:561 */
			reg = < 0x40012000 0x400 >;                                  /* in zephyr/dts/arm/st/f4/stm32f4.dtsi:562 */
			clocks = < &rcc 0x44 0x100 >;                                /* in zephyr/dts/arm/st/f4/stm32f4.dtsi:563 */
			clock-names = "adcx";                                        /* in zephyr/dts/arm/st/f4/stm32f4.dtsi:564 */
			interrupts = < 0x12 0x0 >;                                   /* in zephyr/dts/arm/st/f4/stm32f4.dtsi:565 */
			#io-channel-cells = < 0x1 >;                                 /* in zephyr/dts/arm/st/f4/stm32f4.dtsi:566 */
			resolutions = < 0x607804 0x517804 0x427804 0x337804 >;       /* in zephyr/dts/arm/st/f4/stm32f4.dtsi:567 */
			sampling-times = < 0x3 0xf 0x1c 0x38 0x54 0x70 0x90 0x1e0 >; /* in zephyr/dts/arm/st/f4/stm32f4.dtsi:571 */
			st,adc-clock-source = "SYNC";                                /* in zephyr/dts/arm/st/f4/stm32f4.dtsi:572 */
			st,adc-sequencer = "programmable";                           /* in zephyr/dts/arm/st/f4/stm32f4.dtsi:573 */
			st,adc-oversampler = "none";                                 /* in zephyr/dts/arm/st/f4/stm32f4.dtsi:574 */
			st,adc-internal-regulator = "none";                          /* in zephyr/dts/arm/st/f4/stm32f4.dtsi:575 */
			status = "disabled";                                         /* in zephyr/dts/arm/st/f4/stm32f4.dtsi:576 */
			phandle = < 0x1b >;                                          /* in zephyr/dts/arm/st/f4/stm32f411.dtsi:73 */
		};

		/* node '/soc/dma@40026000' defined in zephyr/dts/arm/st/f4/stm32f4.dtsi:579 */
		dma1: dma@40026000 {
			compatible = "st,stm32-dma-v1";                                                      /* in zephyr/dts/arm/st/f4/stm32f4.dtsi:580 */
			#dma-cells = < 0x4 >;                                                                /* in zephyr/dts/arm/st/f4/stm32f4.dtsi:581 */
			reg = < 0x40026000 0x400 >;                                                          /* in zephyr/dts/arm/st/f4/stm32f4.dtsi:582 */
			interrupts = < 0xb 0x0 0xc 0x0 0xd 0x0 0xe 0x0 0xf 0x0 0x10 0x0 0x11 0x0 0x2f 0x0 >; /* in zephyr/dts/arm/st/f4/stm32f4.dtsi:583 */
			clocks = < &rcc 0x30 0x200000 >;                                                     /* in zephyr/dts/arm/st/f4/stm32f4.dtsi:584 */
			status = "disabled";                                                                 /* in zephyr/dts/arm/st/f4/stm32f4.dtsi:585 */
			phandle = < 0x14 >;                                                                  /* in zephyr/dts/arm/st/f4/stm32f401.dtsi:61 */
		};

		/* node '/soc/dma@40026400' defined in zephyr/dts/arm/st/f4/stm32f4.dtsi:588 */
		dma2: dma@40026400 {
			compatible = "st,stm32-dma-v1";                                                           /* in zephyr/dts/arm/st/f4/stm32f4.dtsi:589 */
			#dma-cells = < 0x4 >;                                                                     /* in zephyr/dts/arm/st/f4/stm32f4.dtsi:590 */
			reg = < 0x40026400 0x400 >;                                                               /* in zephyr/dts/arm/st/f4/stm32f4.dtsi:591 */
			interrupts = < 0x38 0x0 0x39 0x0 0x3a 0x0 0x3b 0x0 0x3c 0x0 0x44 0x0 0x45 0x0 0x46 0x0 >; /* in zephyr/dts/arm/st/f4/stm32f4.dtsi:592 */
			clocks = < &rcc 0x30 0x400000 >;                                                          /* in zephyr/dts/arm/st/f4/stm32f4.dtsi:593 */
			st,mem2mem;                                                                               /* in zephyr/dts/arm/st/f4/stm32f4.dtsi:594 */
			status = "disabled";                                                                      /* in zephyr/dts/arm/st/f4/stm32f4.dtsi:595 */
			phandle = < 0x15 >;                                                                       /* in zephyr/dts/arm/st/f4/stm32f411.dtsi:39 */
		};

		/* node '/soc/sdmmc@40012c00' defined in zephyr/dts/arm/st/f4/stm32f4.dtsi:598 */
		sdmmc1: sdmmc@40012c00 {
			compatible = "st,stm32-sdmmc"; /* in zephyr/dts/arm/st/f4/stm32f4.dtsi:599 */
			reg = < 0x40012c00 0x400 >;    /* in zephyr/dts/arm/st/f4/stm32f4.dtsi:600 */
			clocks = < &rcc 0x44 0x800 >,
			         < &rcc 0x7 0xff >;    /* in zephyr/dts/arm/st/f4/stm32f4.dtsi:601 */
			resets = < &rctl 0x48b >;      /* in zephyr/dts/arm/st/f4/stm32f4.dtsi:603 */
			interrupts = < 0x31 0x0 >;     /* in zephyr/dts/arm/st/f4/stm32f4.dtsi:604 */
			status = "disabled";           /* in zephyr/dts/arm/st/f4/stm32f4.dtsi:605 */
		};

		/* node '/soc/spi@40003800' defined in zephyr/dts/arm/st/f4/stm32f401.dtsi:21 */
		spi2: spi@40003800 {
			compatible = "st,stm32-spi";            /* in zephyr/dts/arm/st/f4/stm32f401.dtsi:22 */
			#address-cells = < 0x1 >;               /* in zephyr/dts/arm/st/f4/stm32f401.dtsi:23 */
			#size-cells = < 0x0 >;                  /* in zephyr/dts/arm/st/f4/stm32f401.dtsi:24 */
			reg = < 0x40003800 0x400 >;             /* in zephyr/dts/arm/st/f4/stm32f401.dtsi:25 */
			clocks = < &rcc 0x40 0x4000 >;          /* in zephyr/dts/arm/st/f4/stm32f401.dtsi:26 */
			interrupts = < 0x24 0x5 >;              /* in zephyr/dts/arm/st/f4/stm32f401.dtsi:27 */
			st,spi-data-width = "limited-8-16-bit"; /* in zephyr/dts/arm/st/f4/stm32f401.dtsi:28 */
			status = "disabled";                    /* in zephyr/dts/arm/st/f4/stm32f401.dtsi:29 */
		};

		/* node '/soc/spi@40003c00' defined in zephyr/dts/arm/st/f4/stm32f401.dtsi:32 */
		spi3: spi@40003c00 {
			compatible = "st,stm32-spi";            /* in zephyr/dts/arm/st/f4/stm32f401.dtsi:33 */
			#address-cells = < 0x1 >;               /* in zephyr/dts/arm/st/f4/stm32f401.dtsi:34 */
			#size-cells = < 0x0 >;                  /* in zephyr/dts/arm/st/f4/stm32f401.dtsi:35 */
			reg = < 0x40003c00 0x400 >;             /* in zephyr/dts/arm/st/f4/stm32f401.dtsi:36 */
			clocks = < &rcc 0x40 0x8000 >;          /* in zephyr/dts/arm/st/f4/stm32f401.dtsi:37 */
			interrupts = < 0x33 0x5 >;              /* in zephyr/dts/arm/st/f4/stm32f401.dtsi:38 */
			st,spi-data-width = "limited-8-16-bit"; /* in zephyr/dts/arm/st/f4/stm32f401.dtsi:39 */
			status = "disabled";                    /* in zephyr/dts/arm/st/f4/stm32f401.dtsi:40 */
		};

		/* node '/soc/spi@40013400' defined in zephyr/dts/arm/st/f4/stm32f401.dtsi:43 */
		spi4: spi@40013400 {
			compatible = "st,stm32-spi";            /* in zephyr/dts/arm/st/f4/stm32f401.dtsi:44 */
			#address-cells = < 0x1 >;               /* in zephyr/dts/arm/st/f4/stm32f401.dtsi:45 */
			#size-cells = < 0x0 >;                  /* in zephyr/dts/arm/st/f4/stm32f401.dtsi:46 */
			reg = < 0x40013400 0x400 >;             /* in zephyr/dts/arm/st/f4/stm32f401.dtsi:47 */
			clocks = < &rcc 0x44 0x2000 >;          /* in zephyr/dts/arm/st/f4/stm32f401.dtsi:48 */
			interrupts = < 0x54 0x5 >;              /* in zephyr/dts/arm/st/f4/stm32f401.dtsi:49 */
			st,spi-data-width = "limited-8-16-bit"; /* in zephyr/dts/arm/st/f4/stm32f401.dtsi:50 */
			status = "disabled";                    /* in zephyr/dts/arm/st/f4/stm32f401.dtsi:51 */
		};

		/* node '/soc/i2s@40003800' defined in zephyr/dts/arm/st/f4/stm32f401.dtsi:54 */
		i2s2: i2s@40003800 {
			compatible = "st,stm32-i2s";        /* in zephyr/dts/arm/st/f4/stm32f401.dtsi:55 */
			#address-cells = < 0x1 >;           /* in zephyr/dts/arm/st/f4/stm32f401.dtsi:56 */
			#size-cells = < 0x0 >;              /* in zephyr/dts/arm/st/f4/stm32f401.dtsi:57 */
			reg = < 0x40003800 0x400 >;         /* in zephyr/dts/arm/st/f4/stm32f401.dtsi:58 */
			clocks = < &rcc 0x40 0x4000 >;      /* in zephyr/dts/arm/st/f4/stm32f401.dtsi:59 */
			interrupts = < 0x24 0x5 >;          /* in zephyr/dts/arm/st/f4/stm32f401.dtsi:60 */
			dmas = < &dma1 0x4 0x0 0x400 0x3 >,
			       < &dma1 0x3 0x0 0x400 0x3 >; /* in zephyr/dts/arm/st/f4/stm32f401.dtsi:61 */
			dma-names = "tx",
			            "rx";                   /* in zephyr/dts/arm/st/f4/stm32f401.dtsi:63 */
			status = "disabled";                /* in zephyr/dts/arm/st/f4/stm32f401.dtsi:64 */
		};

		/* node '/soc/i2s@40003c00' defined in zephyr/dts/arm/st/f4/stm32f401.dtsi:67 */
		i2s3: i2s@40003c00 {
			compatible = "st,stm32-i2s";        /* in zephyr/dts/arm/st/f4/stm32f401.dtsi:68 */
			#address-cells = < 0x1 >;           /* in zephyr/dts/arm/st/f4/stm32f401.dtsi:69 */
			#size-cells = < 0x0 >;              /* in zephyr/dts/arm/st/f4/stm32f401.dtsi:70 */
			reg = < 0x40003c00 0x400 >;         /* in zephyr/dts/arm/st/f4/stm32f401.dtsi:71 */
			clocks = < &rcc 0x40 0x8000 >;      /* in zephyr/dts/arm/st/f4/stm32f401.dtsi:72 */
			interrupts = < 0x33 0x5 >;          /* in zephyr/dts/arm/st/f4/stm32f401.dtsi:73 */
			dmas = < &dma1 0x5 0x0 0x400 0x3 >,
			       < &dma1 0x0 0x0 0x400 0x3 >; /* in zephyr/dts/arm/st/f4/stm32f401.dtsi:74 */
			dma-names = "tx",
			            "rx";                   /* in zephyr/dts/arm/st/f4/stm32f401.dtsi:76 */
			status = "disabled";                /* in zephyr/dts/arm/st/f4/stm32f401.dtsi:77 */
		};

		/* node '/soc/spi@40015000' defined in zephyr/dts/arm/st/f4/stm32f411.dtsi:21 */
		spi5: spi@40015000 {
			compatible = "st,stm32-spi";            /* in zephyr/dts/arm/st/f4/stm32f411.dtsi:22 */
			#address-cells = < 0x1 >;               /* in zephyr/dts/arm/st/f4/stm32f411.dtsi:23 */
			#size-cells = < 0x0 >;                  /* in zephyr/dts/arm/st/f4/stm32f411.dtsi:24 */
			reg = < 0x40015000 0x400 >;             /* in zephyr/dts/arm/st/f4/stm32f411.dtsi:25 */
			clocks = < &rcc 0x44 0x100000 >;        /* in zephyr/dts/arm/st/f4/stm32f411.dtsi:26 */
			interrupts = < 0x55 0x5 >;              /* in zephyr/dts/arm/st/f4/stm32f411.dtsi:27 */
			st,spi-data-width = "limited-8-16-bit"; /* in zephyr/dts/arm/st/f4/stm32f411.dtsi:28 */
			status = "disabled";                    /* in zephyr/dts/arm/st/f4/stm32f411.dtsi:29 */
		};

		/* node '/soc/i2s@40013000' defined in zephyr/dts/arm/st/f4/stm32f411.dtsi:32 */
		i2s1: arduino_i2s: i2s@40013000 {
			compatible = "st,stm32-i2s";               /* in zephyr/dts/arm/st/f4/stm32f411.dtsi:33 */
			#address-cells = < 0x1 >;                  /* in zephyr/dts/arm/st/f4/stm32f411.dtsi:34 */
			#size-cells = < 0x0 >;                     /* in zephyr/dts/arm/st/f4/stm32f411.dtsi:35 */
			reg = < 0x40013000 0x400 >;                /* in zephyr/dts/arm/st/f4/stm32f411.dtsi:36 */
			clocks = < &rcc 0x44 0x1000 >;             /* in zephyr/dts/arm/st/f4/stm32f411.dtsi:37 */
			interrupts = < 0x23 0x5 >;                 /* in zephyr/dts/arm/st/f4/stm32f411.dtsi:38 */
			dmas = < &dma2 0x3 0x3 0x400 0x3 >,
			       < &dma2 0x2 0x3 0x400 0x3 >;        /* in zephyr/dts/arm/st/f4/stm32f411.dtsi:39 */
			dma-names = "tx",
			            "rx";                          /* in zephyr/dts/arm/st/f4/stm32f411.dtsi:41 */
			status = "disabled";                       /* in zephyr/dts/arm/st/f4/stm32f411.dtsi:42 */
			pinctrl-0 = < &i2s1_ck_pa5 &i2s1_sd_pa7 >; /* in zephyr/boards/st/nucleo_f411re/nucleo_f411re.dts:111 */
			pinctrl-names = "default";                 /* in zephyr/boards/st/nucleo_f411re/nucleo_f411re.dts:112 */
		};

		/* node '/soc/i2s@40013400' defined in zephyr/dts/arm/st/f4/stm32f411.dtsi:45 */
		i2s4: i2s@40013400 {
			compatible = "st,stm32-i2s";        /* in zephyr/dts/arm/st/f4/stm32f411.dtsi:46 */
			#address-cells = < 0x1 >;           /* in zephyr/dts/arm/st/f4/stm32f411.dtsi:47 */
			#size-cells = < 0x0 >;              /* in zephyr/dts/arm/st/f4/stm32f411.dtsi:48 */
			reg = < 0x40013400 0x400 >;         /* in zephyr/dts/arm/st/f4/stm32f411.dtsi:49 */
			clocks = < &rcc 0x44 0x2000 >;      /* in zephyr/dts/arm/st/f4/stm32f411.dtsi:50 */
			interrupts = < 0x54 0x5 >;          /* in zephyr/dts/arm/st/f4/stm32f411.dtsi:51 */
			dmas = < &dma2 0x1 0x4 0x400 0x3 >,
			       < &dma2 0x0 0x4 0x400 0x3 >; /* in zephyr/dts/arm/st/f4/stm32f411.dtsi:52 */
			dma-names = "tx",
			            "rx";                   /* in zephyr/dts/arm/st/f4/stm32f411.dtsi:54 */
			status = "disabled";                /* in zephyr/dts/arm/st/f4/stm32f411.dtsi:55 */
		};

		/* node '/soc/i2s@40015000' defined in zephyr/dts/arm/st/f4/stm32f411.dtsi:58 */
		i2s5: i2s@40015000 {
			compatible = "st,stm32-i2s";        /* in zephyr/dts/arm/st/f4/stm32f411.dtsi:59 */
			#address-cells = < 0x1 >;           /* in zephyr/dts/arm/st/f4/stm32f411.dtsi:60 */
			#size-cells = < 0x0 >;              /* in zephyr/dts/arm/st/f4/stm32f411.dtsi:61 */
			reg = < 0x40015000 0x400 >;         /* in zephyr/dts/arm/st/f4/stm32f411.dtsi:62 */
			clocks = < &rcc 0x44 0x100000 >;    /* in zephyr/dts/arm/st/f4/stm32f411.dtsi:63 */
			interrupts = < 0x55 0x5 >;          /* in zephyr/dts/arm/st/f4/stm32f411.dtsi:64 */
			dmas = < &dma2 0x6 0x7 0x400 0x3 >,
			       < &dma2 0x5 0x7 0x400 0x3 >; /* in zephyr/dts/arm/st/f4/stm32f411.dtsi:65 */
			dma-names = "tx",
			            "rx";                   /* in zephyr/dts/arm/st/f4/stm32f411.dtsi:67 */
			status = "disabled";                /* in zephyr/dts/arm/st/f4/stm32f411.dtsi:68 */
		};
	};

	/* node '/cpus' defined in zephyr/dts/arm/st/f4/stm32f4.dtsi:31 */
	cpus {
		#address-cells = < 0x1 >; /* in zephyr/dts/arm/st/f4/stm32f4.dtsi:32 */
		#size-cells = < 0x0 >;    /* in zephyr/dts/arm/st/f4/stm32f4.dtsi:33 */

		/* node '/cpus/cpu@0' defined in zephyr/dts/arm/st/f4/stm32f4.dtsi:35 */
		cpu0: cpu@0 {
			device_type = "cpu";           /* in zephyr/dts/arm/st/f4/stm32f4.dtsi:36 */
			compatible = "arm,cortex-m4f"; /* in zephyr/dts/arm/st/f4/stm32f4.dtsi:37 */
			reg = < 0x0 >;                 /* in zephyr/dts/arm/st/f4/stm32f4.dtsi:38 */
			cpu-power-states = < &stop >;  /* in zephyr/dts/arm/st/f4/stm32f4.dtsi:39 */
		};

		/* node '/cpus/power-states' defined in zephyr/dts/arm/st/f4/stm32f4.dtsi:42 */
		power-states {

			/* node '/cpus/power-states/stop' defined in zephyr/dts/arm/st/f4/stm32f4.dtsi:43 */
			stop: stop {
				compatible = "zephyr,power-state";    /* in zephyr/dts/arm/st/f4/stm32f4.dtsi:44 */
				power-state-name = "suspend-to-idle"; /* in zephyr/dts/arm/st/f4/stm32f4.dtsi:45 */
				min-residency-us = < 0x190 >;         /* in zephyr/dts/arm/st/f4/stm32f4.dtsi:52 */
				exit-latency-us = < 0x12c >;          /* in zephyr/dts/arm/st/f4/stm32f4.dtsi:53 */
				phandle = < 0x18 >;                   /* in zephyr/dts/arm/st/f4/stm32f4.dtsi:39 */
			};
		};
	};

	/* node '/memory@20000000' defined in zephyr/dts/arm/st/f4/stm32f4.dtsi:58 */
	sram0: memory@20000000 {
		compatible = "zephyr,memory-region",
		             "mmio-sram";            /* in zephyr/dts/arm/st/f4/stm32f4.dtsi:59 */
		zephyr,memory-region = "SRAM0";      /* in zephyr/dts/arm/st/f4/stm32f4.dtsi:60 */
		reg = < 0x20000000 0x20000 >;        /* in zephyr/dts/arm/st/f4/stm32f411Xe.dtsi:11 */
	};

	/* node '/clocks' defined in zephyr/dts/arm/st/f4/stm32f4.dtsi:63 */
	clocks {

		/* node '/clocks/clk-hse' defined in zephyr/dts/arm/st/f4/stm32f4.dtsi:64 */
		clk_hse: clk-hse {
			#clock-cells = < 0x0 >;            /* in zephyr/dts/arm/st/f4/stm32f4.dtsi:65 */
			compatible = "st,stm32-hse-clock"; /* in zephyr/dts/arm/st/f4/stm32f4.dtsi:66 */
			hse-bypass;                        /* in zephyr/boards/st/nucleo_f411re/nucleo_f411re.dts:55 */
			clock-frequency = < 0x7a1200 >;    /* in zephyr/boards/st/nucleo_f411re/nucleo_f411re.dts:56 */
			status = "okay";                   /* in zephyr/boards/st/nucleo_f411re/nucleo_f411re.dts:57 */
			phandle = < 0x19 >;                /* in zephyr/boards/st/nucleo_f411re/nucleo_f411re.dts:65 */
		};

		/* node '/clocks/clk-hsi' defined in zephyr/dts/arm/st/f4/stm32f4.dtsi:70 */
		clk_hsi: clk-hsi {
			#clock-cells = < 0x0 >;         /* in zephyr/dts/arm/st/f4/stm32f4.dtsi:71 */
			compatible = "fixed-clock";     /* in zephyr/dts/arm/st/f4/stm32f4.dtsi:72 */
			clock-frequency = < 0xf42400 >; /* in zephyr/dts/arm/st/f4/stm32f4.dtsi:73 */
			status = "disabled";            /* in zephyr/dts/arm/st/f4/stm32f4.dtsi:74 */
		};

		/* node '/clocks/clk-lse' defined in zephyr/dts/arm/st/f4/stm32f4.dtsi:77 */
		clk_lse: clk-lse {
			#clock-cells = < 0x0 >;       /* in zephyr/dts/arm/st/f4/stm32f4.dtsi:78 */
			compatible = "fixed-clock";   /* in zephyr/dts/arm/st/f4/stm32f4.dtsi:79 */
			clock-frequency = < 0x8000 >; /* in zephyr/dts/arm/st/f4/stm32f4.dtsi:80 */
			status = "disabled";          /* in zephyr/dts/arm/st/f4/stm32f4.dtsi:81 */
		};

		/* node '/clocks/clk-lsi' defined in zephyr/dts/arm/st/f4/stm32f4.dtsi:84 */
		clk_lsi: clk-lsi {
			#clock-cells = < 0x0 >;       /* in zephyr/dts/arm/st/f4/stm32f4.dtsi:85 */
			compatible = "fixed-clock";   /* in zephyr/dts/arm/st/f4/stm32f4.dtsi:86 */
			clock-frequency = < 0x7d00 >; /* in zephyr/dts/arm/st/f4/stm32f4.dtsi:87 */
			status = "okay";              /* in zephyr/boards/st/nucleo_f411re/nucleo_f411re.dts:51 */
		};

		/* node '/clocks/pll' defined in zephyr/dts/arm/st/f4/stm32f4.dtsi:91 */
		pll: pll {
			#clock-cells = < 0x0 >;              /* in zephyr/dts/arm/st/f4/stm32f4.dtsi:92 */
			compatible = "st,stm32f4-pll-clock"; /* in zephyr/dts/arm/st/f4/stm32f4.dtsi:93 */
			div-m = < 0x8 >;                     /* in zephyr/boards/st/nucleo_f411re/nucleo_f411re.dts:61 */
			mul-n = < 0x180 >;                   /* in zephyr/boards/st/nucleo_f411re/nucleo_f411re.dts:62 */
			div-p = < 0x4 >;                     /* in zephyr/boards/st/nucleo_f411re/nucleo_f411re.dts:63 */
			div-q = < 0x8 >;                     /* in zephyr/boards/st/nucleo_f411re/nucleo_f411re.dts:64 */
			clocks = < &clk_hse >;               /* in zephyr/boards/st/nucleo_f411re/nucleo_f411re.dts:65 */
			status = "okay";                     /* in zephyr/boards/st/nucleo_f411re/nucleo_f411re.dts:66 */
			phandle = < 0x2 >;                   /* in zephyr/boards/st/nucleo_f411re/nucleo_f411re.dts:70 */
		};

		/* node '/clocks/plli2s' defined in zephyr/dts/arm/st/f4/stm32f401.dtsi:11 */
		plli2s: plli2s {
			#clock-cells = < 0x0 >;                   /* in zephyr/dts/arm/st/f4/stm32f411.dtsi:12 */
			compatible = "st,stm32f411-plli2s-clock"; /* in zephyr/dts/arm/st/f4/stm32f411.dtsi:13 */
			status = "disabled";                      /* in zephyr/dts/arm/st/f4/stm32f411.dtsi:14 */
		};
	};

	/* node '/mcos' defined in zephyr/dts/arm/st/f4/stm32f4.dtsi:98 */
	mcos {

		/* node '/mcos/mco1' defined in zephyr/dts/arm/st/f4/stm32f4.dtsi:99 */
		mco1: mco1 {
			compatible = "st,stm32-clock-mco"; /* in zephyr/dts/arm/st/f4/stm32f4.dtsi:100 */
			status = "disabled";               /* in zephyr/dts/arm/st/f4/stm32f4.dtsi:101 */
		};

		/* node '/mcos/mco2' defined in zephyr/dts/arm/st/f4/stm32f4.dtsi:104 */
		mco2: mco2 {
			compatible = "st,stm32-clock-mco"; /* in zephyr/dts/arm/st/f4/stm32f4.dtsi:105 */
			status = "disabled";               /* in zephyr/dts/arm/st/f4/stm32f4.dtsi:106 */
		};
	};

	/* node '/power@40007000' defined in zephyr/dts/arm/st/f4/stm32f4.dtsi:609 */
	pwr: power@40007000 {
		compatible = "st,stm32-pwr"; /* in zephyr/dts/arm/st/f4/stm32f4.dtsi:610 */
		reg = < 0x40007000 0x400 >;  /* in zephyr/dts/arm/st/f4/stm32f4.dtsi:611 */
		status = "disabled";         /* in zephyr/dts/arm/st/f4/stm32f4.dtsi:612 */
		wkup-pins-nb = < 0x1 >;      /* in zephyr/dts/arm/st/f4/stm32f4.dtsi:614 */
		#address-cells = < 0x1 >;    /* in zephyr/dts/arm/st/f4/stm32f4.dtsi:616 */
		#size-cells = < 0x0 >;       /* in zephyr/dts/arm/st/f4/stm32f4.dtsi:617 */

		/* node '/power@40007000/wkup-pin@1' defined in zephyr/dts/arm/st/f4/stm32f4.dtsi:619 */
		wkup-pin@1 {
			reg = < 0x1 >;                   /* in zephyr/dts/arm/st/f4/stm32f4.dtsi:620 */
			wkup-gpios = < &gpioa 0x0 0x1 >; /* in zephyr/dts/arm/st/f4/stm32f4.dtsi:621 */
		};
	};

	/* node '/dietemp' defined in zephyr/dts/arm/st/f4/stm32f4.dtsi:625 */
	die_temp: dietemp {
		compatible = "st,stm32-temp-cal"; /* in zephyr/dts/arm/st/f4/stm32f4.dtsi:626 */
		ts-cal1-addr = < 0x1fff7a2c >;    /* in zephyr/dts/arm/st/f4/stm32f4.dtsi:627 */
		ts-cal2-addr = < 0x1fff7a2e >;    /* in zephyr/dts/arm/st/f4/stm32f4.dtsi:628 */
		ts-cal1-temp = < 0x1e >;          /* in zephyr/dts/arm/st/f4/stm32f4.dtsi:629 */
		ts-cal2-temp = < 0x6e >;          /* in zephyr/dts/arm/st/f4/stm32f4.dtsi:630 */
		ts-cal-vrefanalog = < 0xce4 >;    /* in zephyr/dts/arm/st/f4/stm32f4.dtsi:631 */
		status = "disabled";              /* in zephyr/dts/arm/st/f4/stm32f4.dtsi:633 */
		io-channels = < &adc1 0x12 >;     /* in zephyr/dts/arm/st/f4/stm32f411.dtsi:73 */
	};

	/* node '/vref' defined in zephyr/dts/arm/st/f4/stm32f4.dtsi:636 */
	vref: vref {
		compatible = "st,stm32-vref";      /* in zephyr/dts/arm/st/f4/stm32f4.dtsi:637 */
		vrefint-cal-addr = < 0x1fff7a2a >; /* in zephyr/dts/arm/st/f4/stm32f4.dtsi:638 */
		vrefint-cal-mv = < 0xce4 >;        /* in zephyr/dts/arm/st/f4/stm32f4.dtsi:639 */
		io-channels = < &adc1 0x11 >;      /* in zephyr/dts/arm/st/f4/stm32f4.dtsi:640 */
		status = "disabled";               /* in zephyr/dts/arm/st/f4/stm32f4.dtsi:641 */
	};

	/* node '/vbat' defined in zephyr/dts/arm/st/f4/stm32f4.dtsi:644 */
	vbat: vbat {
		compatible = "st,stm32-vbat"; /* in zephyr/dts/arm/st/f4/stm32f4.dtsi:645 */
		ratio = < 0x4 >;              /* in zephyr/dts/arm/st/f4/stm32f4.dtsi:646 */
		io-channels = < &adc1 0x12 >; /* in zephyr/dts/arm/st/f4/stm32f4.dtsi:647 */
		status = "disabled";          /* in zephyr/dts/arm/st/f4/stm32f4.dtsi:648 */
	};

	/* node '/otgfs_phy' defined in zephyr/dts/arm/st/f4/stm32f4.dtsi:651 */
	otgfs_phy: otgfs_phy {
		compatible = "usb-nop-xceiv"; /* in zephyr/dts/arm/st/f4/stm32f4.dtsi:652 */
		#phy-cells = < 0x0 >;         /* in zephyr/dts/arm/st/f4/stm32f4.dtsi:653 */
		phandle = < 0x13 >;           /* in zephyr/dts/arm/st/f4/stm32f4.dtsi:323 */
	};

	/* node '/smbus1' defined in zephyr/dts/arm/st/f4/stm32f4.dtsi:656 */
	smbus1: smbus1 {
		compatible = "st,stm32-smbus"; /* in zephyr/dts/arm/st/f4/stm32f4.dtsi:657 */
		#address-cells = < 0x1 >;      /* in zephyr/dts/arm/st/f4/stm32f4.dtsi:658 */
		#size-cells = < 0x0 >;         /* in zephyr/dts/arm/st/f4/stm32f4.dtsi:659 */
		i2c = < &i2c1 >;               /* in zephyr/dts/arm/st/f4/stm32f4.dtsi:660 */
		status = "disabled";           /* in zephyr/dts/arm/st/f4/stm32f4.dtsi:661 */
	};

	/* node '/smbus2' defined in zephyr/dts/arm/st/f4/stm32f4.dtsi:664 */
	smbus2: smbus2 {
		compatible = "st,stm32-smbus"; /* in zephyr/dts/arm/st/f4/stm32f4.dtsi:665 */
		#address-cells = < 0x1 >;      /* in zephyr/dts/arm/st/f4/stm32f4.dtsi:666 */
		#size-cells = < 0x0 >;         /* in zephyr/dts/arm/st/f4/stm32f4.dtsi:667 */
		i2c = < &i2c2 >;               /* in zephyr/dts/arm/st/f4/stm32f4.dtsi:668 */
		status = "disabled";           /* in zephyr/dts/arm/st/f4/stm32f4.dtsi:669 */
	};

	/* node '/smbus3' defined in zephyr/dts/arm/st/f4/stm32f4.dtsi:672 */
	smbus3: smbus3 {
		compatible = "st,stm32-smbus"; /* in zephyr/dts/arm/st/f4/stm32f4.dtsi:673 */
		#address-cells = < 0x1 >;      /* in zephyr/dts/arm/st/f4/stm32f4.dtsi:674 */
		#size-cells = < 0x0 >;         /* in zephyr/dts/arm/st/f4/stm32f4.dtsi:675 */
		i2c = < &i2c3 >;               /* in zephyr/dts/arm/st/f4/stm32f4.dtsi:676 */
		status = "disabled";           /* in zephyr/dts/arm/st/f4/stm32f4.dtsi:677 */
	};

	/* node '/connector' defined in zephyr/boards/st/nucleo_f411re/arduino_r3_connector.dtsi:10 */
	arduino_header: connector {
		compatible = "arduino-header-r3";          /* in zephyr/boards/st/nucleo_f411re/arduino_r3_connector.dtsi:11 */
		#gpio-cells = < 0x2 >;                     /* in zephyr/boards/st/nucleo_f411re/arduino_r3_connector.dtsi:12 */
		gpio-map-mask = < 0xffffffff 0xffffffc0 >; /* in zephyr/boards/st/nucleo_f411re/arduino_r3_connector.dtsi:13 */
		gpio-map-pass-thru = < 0x0 0x3f >;         /* in zephyr/boards/st/nucleo_f411re/arduino_r3_connector.dtsi:14 */
		gpio-map = < 0x0 0x0 &gpioa 0x0 0x0 >,
		           < 0x1 0x0 &gpioa 0x1 0x0 >,
		           < 0x2 0x0 &gpioa 0x4 0x0 >,
		           < 0x3 0x0 &gpiob 0x0 0x0 >,
		           < 0x4 0x0 &gpioc 0x1 0x0 >,
		           < 0x5 0x0 &gpioc 0x0 0x0 >,
		           < 0x6 0x0 &gpioa 0x3 0x0 >,
		           < 0x7 0x0 &gpioa 0x2 0x0 >,
		           < 0x8 0x0 &gpioa 0xa 0x0 >,
		           < 0x9 0x0 &gpiob 0x3 0x0 >,
		           < 0xa 0x0 &gpiob 0x5 0x0 >,
		           < 0xb 0x0 &gpiob 0x4 0x0 >,
		           < 0xc 0x0 &gpiob 0xa 0x0 >,
		           < 0xd 0x0 &gpioa 0x8 0x0 >,
		           < 0xe 0x0 &gpioa 0x9 0x0 >,
		           < 0xf 0x0 &gpioc 0x7 0x0 >,
		           < 0x10 0x0 &gpiob 0x6 0x0 >,
		           < 0x11 0x0 &gpioa 0x7 0x0 >,
		           < 0x12 0x0 &gpioa 0x6 0x0 >,
		           < 0x13 0x0 &gpioa 0x5 0x0 >,
		           < 0x14 0x0 &gpiob 0x9 0x0 >,
		           < 0x15 0x0 &gpiob 0x8 0x0 >;    /* in zephyr/boards/st/nucleo_f411re/arduino_r3_connector.dtsi:15 */
	};

	/* node '/st-morpho-header' defined in zephyr/boards/st/nucleo_f411re/st_morpho_connector.dtsi:10 */
	st_morpho_header: st-morpho-header {
		compatible = "st-morpho-header";        /* in zephyr/boards/st/nucleo_f411re/st_morpho_connector.dtsi:11 */
		#gpio-cells = < 0x2 >;                  /* in zephyr/boards/st/nucleo_f411re/st_morpho_connector.dtsi:12 */
		gpio-map-mask = < 0xff 0x0 >;           /* in zephyr/boards/st/nucleo_f411re/st_morpho_connector.dtsi:13 */
		gpio-map-pass-thru = < 0x0 0x7f >;      /* in zephyr/boards/st/nucleo_f411re/st_morpho_connector.dtsi:14 */
		gpio-map = < 0x0 0x0 &gpioc 0xa 0x0 >,
		           < 0x1 0x0 &gpioc 0xb 0x0 >,
		           < 0x2 0x0 &gpioc 0xc 0x0 >,
		           < 0x3 0x0 &gpiod 0x2 0x0 >,
		           < 0xc 0x0 &gpioa 0xd 0x0 >,
		           < 0xe 0x0 &gpioa 0xe 0x0 >,
		           < 0x10 0x0 &gpioa 0xf 0x0 >,
		           < 0x14 0x0 &gpiob 0x7 0x0 >,
		           < 0x16 0x0 &gpioc 0xd 0x0 >,
		           < 0x18 0x0 &gpioc 0xe 0x0 >,
		           < 0x1a 0x0 &gpioc 0xf 0x0 >,
		           < 0x1b 0x0 &gpioa 0x0 0x0 >,
		           < 0x1c 0x0 &gpioh 0x0 0x0 >,
		           < 0x1d 0x0 &gpioa 0x1 0x0 >,
		           < 0x1e 0x0 &gpioh 0x1 0x0 >,
		           < 0x1f 0x0 &gpioa 0x4 0x0 >,
		           < 0x21 0x0 &gpiob 0x0 0x0 >,
		           < 0x22 0x0 &gpioc 0x2 0x0 >,
		           < 0x23 0x0 &gpioc 0x1 0x0 >,
		           < 0x24 0x0 &gpioc 0x3 0x0 >,
		           < 0x25 0x0 &gpioc 0x0 0x0 >,
		           < 0x48 0x0 &gpioc 0x9 0x0 >,
		           < 0x49 0x0 &gpioc 0x8 0x0 >,
		           < 0x4a 0x0 &gpiob 0x8 0x0 >,
		           < 0x4b 0x0 &gpioc 0x6 0x0 >,
		           < 0x4c 0x0 &gpiob 0x9 0x0 >,
		           < 0x4d 0x0 &gpioc 0x5 0x0 >,
		           < 0x52 0x0 &gpioa 0x5 0x0 >,
		           < 0x53 0x0 &gpioa 0xc 0x0 >,
		           < 0x54 0x0 &gpioa 0x6 0x0 >,
		           < 0x55 0x0 &gpioa 0xb 0x0 >,
		           < 0x56 0x0 &gpioa 0x7 0x0 >,
		           < 0x57 0x0 &gpiob 0xc 0x0 >,
		           < 0x58 0x0 &gpiob 0x6 0x0 >,
		           < 0x5a 0x0 &gpioc 0x7 0x0 >,
		           < 0x5c 0x0 &gpioa 0x9 0x0 >,
		           < 0x5d 0x0 &gpiob 0x2 0x0 >,
		           < 0x5e 0x0 &gpioa 0x8 0x0 >,
		           < 0x5f 0x0 &gpiob 0x1 0x0 >,
		           < 0x60 0x0 &gpiob 0xa 0x0 >,
		           < 0x61 0x0 &gpiob 0xf 0x0 >,
		           < 0x62 0x0 &gpiob 0x4 0x0 >,
		           < 0x63 0x0 &gpiob 0xe 0x0 >,
		           < 0x64 0x0 &gpiob 0x5 0x0 >,
		           < 0x65 0x0 &gpiob 0xd 0x0 >,
		           < 0x66 0x0 &gpiob 0x3 0x0 >,
		           < 0x68 0x0 &gpioa 0xa 0x0 >,
		           < 0x69 0x0 &gpioc 0x4 0x0 >,
		           < 0x6a 0x0 &gpioa 0x2 0x0 >,
		           < 0x6c 0x0 &gpioa 0x3 0x0 >; /* in zephyr/boards/st/nucleo_f411re/st_morpho_connector.dtsi:15 */
	};

	/* node '/leds' defined in zephyr/boards/st/nucleo_f411re/nucleo_f411re.dts:25 */
	leds: leds {
		compatible = "gpio-leds"; /* in iot/nucleo_f411re.overlay:22 */

		/* node '/leds/led_2' defined in zephyr/boards/st/nucleo_f411re/nucleo_f411re.dts:28 */
		green_led_2: led_2 {
			gpios = < &gpioa 0x5 0x0 >; /* in zephyr/boards/st/nucleo_f411re/nucleo_f411re.dts:29 */
			label = "User LD2";         /* in zephyr/boards/st/nucleo_f411re/nucleo_f411re.dts:30 */
		};

		/* node '/leds/node_inbuilt_green_led' defined in iot/nucleo_f411re.overlay:24 */
		label_inbuilt_green_led: node_inbuilt_green_led {
			gpios = < &gpioa 0x5 0x0 >;       /* in iot/nucleo_f411re.overlay:25 */
			label = "user_inbuilt_green_led"; /* in iot/nucleo_f411re.overlay:26 */
		};

		/* node '/leds/node_external_green_led' defined in iot/nucleo_f411re.overlay:29 */
		label_external_green_led: node_external_green_led {
			gpios = < &gpiob 0xd 0x0 >;        /* in iot/nucleo_f411re.overlay:30 */
			label = "user_external_green_led"; /* in iot/nucleo_f411re.overlay:31 */
		};
	};

	/* node '/gpio_keys' defined in zephyr/boards/st/nucleo_f411re/nucleo_f411re.dts:34 */
	gpio_keys {
		compatible = "gpio-keys"; /* in iot/nucleo_f411re.overlay:6 */

		/* node '/gpio_keys/button' defined in zephyr/boards/st/nucleo_f411re/nucleo_f411re.dts:37 */
		user_button: button {
			label = "User";             /* in zephyr/boards/st/nucleo_f411re/nucleo_f411re.dts:38 */
			gpios = < &gpioc 0xd 0x1 >; /* in zephyr/boards/st/nucleo_f411re/nucleo_f411re.dts:39 */
			zephyr,code = < 0xb >;      /* in zephyr/boards/st/nucleo_f411re/nucleo_f411re.dts:40 */
		};

		/* node '/gpio_keys/node_blue_button' defined in iot/nucleo_f411re.overlay:8 */
		label_blue_button: node_blue_button {
			gpios = < &gpioc 0xd 0x1 >; /* in iot/nucleo_f411re.overlay:9 */
			label = "user_blue_button"; /* in iot/nucleo_f411re.overlay:10 */
			zephyr,code = < 0x2 >;      /* in iot/nucleo_f411re.overlay:11 */
		};

		/* node '/gpio_keys/node_wire_button' defined in iot/nucleo_f411re.overlay:14 */
		label_wire_button: node_wire_button {
			gpios = < &gpiob 0xe 0x1 >; /* in iot/nucleo_f411re.overlay:15 */
			label = "user_wire_button"; /* in iot/nucleo_f411re.overlay:16 */
			zephyr,code = < 0x3 >;      /* in iot/nucleo_f411re.overlay:17 */
		};
	};
};
